VERSION ""

NS_ :

BS_:

BU_: ServiceTool DUT

BO_ 2565537529 RQST_0000: 3 ServiceTool
 SG_ ParameterGroupNumber : 0|24@1+ (1,0) [0|16777215] ""  DUT

BO_ 2566838521 CA_ST: 9 ServiceTool
 SG_ AddressAssignment : 64|8@1+ (1,0) [0|255] ""  DUT
 SG_ ArbitraryAddressCapable : 63|1@1+ (1,0) [0|1] ""  DUT
 SG_ IndustryGroup M : 60|3@1+ (1,0) [0|7] ""  DUT
 SG_ VehicleSystemInstance : 56|4@1+ (1,0) [0|15] ""  DUT
 SG_ Function : 40|8@1+ (1,0) [0|255] ""  DUT
 SG_ VehicleSystem m0 : 49|7@1+ (1,0) [0|127] ""  DUT
 SG_ FunctionInstance : 35|5@1+ (1,0) [0|31] ""  DUT
 SG_ ECUInstance : 32|3@1+ (1,0) [0|7] ""  DUT
 SG_ ManufacturerCode : 21|11@1+ (1,0) [0|2047] ""  DUT
 SG_ IdentityNumber : 0|21@1+ (1,0) [0|2097152] ""  DUT
 SG_ VehicleSystem5 m5 : 49|7@1+ (1,0) [0|127] ""  DUT
 SG_ VehicleSystem4 m4 : 49|7@1+ (1,0) [0|127] ""  DUT
 SG_ VehicleSystem3 m3 : 49|7@1+ (1,0) [0|127] ""  DUT
 SG_ VehicleSystem2 m2 : 49|7@1+ (1,0) [0|127] ""  DUT
 SG_ VehicleSystem1 m1 : 49|7@1+ (1,0) [0|127] ""  DUT

BO_ 2565799678 ACL: 8 Vector__XXX
 SG_ VehicleSystem1 m1 : 49|7@1+ (1,0) [0|127] "" Vector__XXX
 SG_ VehicleSystem2 m2 : 49|7@1+ (1,0) [0|127] "" Vector__XXX
 SG_ VehicleSystem3 m3 : 49|7@1+ (1,0) [0|127] "" Vector__XXX
 SG_ VehicleSystem4 m4 : 49|7@1+ (1,0) [0|127] "" Vector__XXX
 SG_ VehicleSystem5 m5 : 49|7@1+ (1,0) [0|127] "" Vector__XXX
 SG_ VehicleSystem m0 : 49|7@1+ (1,0) [0|127] "" Vector__XXX
 SG_ IdentityNumber : 0|21@1+ (1,0) [0|2097152] "" Vector__XXX
 SG_ ManufacturerCode : 21|11@1+ (1,0) [0|2047] "" Vector__XXX
 SG_ ECUInstance : 32|3@1+ (1,0) [0|7] "" Vector__XXX
 SG_ FunctionInstance : 35|5@1+ (1,0) [0|31] "" Vector__XXX
 SG_ Function : 40|8@1+ (1,0) [0|255] "" Vector__XXX
 SG_ VehicleSystemInstance : 56|4@1+ (1,0) [0|15] "" Vector__XXX
 SG_ IndustryGroup M : 60|3@1+ (1,0) [0|7] "" Vector__XXX
 SG_ ArbitraryAddressCapable : 63|1@1+ (1,0) [0|1] "" Vector__XXX

BO_ 2566838912 SOFT_DUT: 8 DUT
 SG_ NmbrOfSftwreIdentificationFields : 0|8@1+ (1,0) [0|250] "steps" Vector__XXX
 SG_ SoftwareIdentification : 8|8@1+ (1.02,0) [0|255] "per byte" Vector__XXX

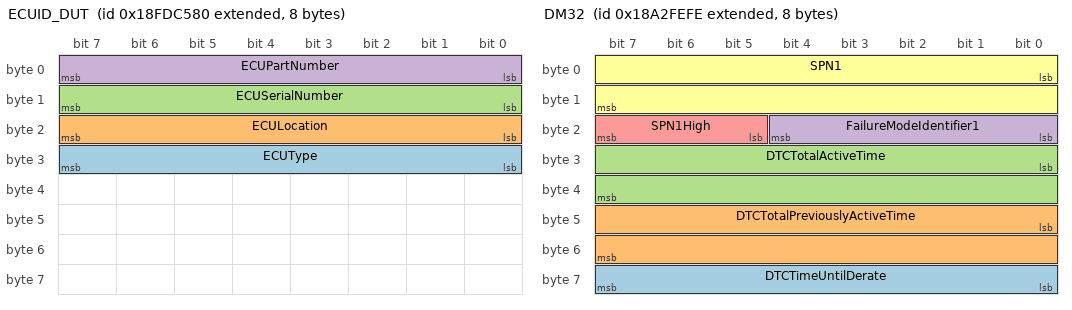
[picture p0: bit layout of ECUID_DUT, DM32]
BO_ 2566768000 ECUID_DUT: 8 DUT
 SG_ ECUType : 24|8@1+ (1.02,0) [0|255] "per byte" Vector__XXX
 SG_ ECULocation : 16|8@1+ (1.02,0) [0|255] "per byte" Vector__XXX
 SG_ ECUSerialNumber : 8|8@1+ (1.02,0) [0|255] "per byte" Vector__XXX
 SG_ ECUPartNumber : 0|8@1+ (1.02,0) [0|255] "per byte" Vector__XXX

BO_ 2565799673 ACL_ST: 8 ServiceTool
 SG_ ArbitraryAddressCapable : 63|1@1+ (1,0) [0|1] "" Vector__XXX
 SG_ IndustryGroup M : 60|3@1+ (1,0) [0|7] "" Vector__XXX
 SG_ VehicleSystemInstance : 56|4@1+ (1,0) [0|15] "" Vector__XXX
 SG_ Function : 40|8@1+ (1,0) [0|255] "" Vector__XXX
 SG_ FunctionInstance : 35|5@1+ (1,0) [0|31] "" Vector__XXX
 SG_ ECUInstance : 32|3@1+ (1,0) [0|7] "" Vector__XXX
 SG_ ManufacturerCode : 21|11@1+ (1,0) [0|2047] "" Vector__XXX
 SG_ IdentityNumber : 0|21@1+ (1,0) [0|2097152] "" Vector__XXX
 SG_ VehicleSystem m0 : 49|7@1+ (1,0) [0|127] "" Vector__XXX
 SG_ VehicleSystem5 m5 : 49|7@1+ (1,0) [0|127] "" Vector__XXX
 SG_ VehicleSystem4 m4 : 49|7@1+ (1,0) [0|127] "" Vector__XXX
 SG_ VehicleSystem3 m3 : 49|7@1+ (1,0) [0|127] "" Vector__XXX
 SG_ VehicleSystem2 m2 : 49|7@1+ (1,0) [0|127] "" Vector__XXX
 SG_ VehicleSystem1 m1 : 49|7@1+ (1,0) [0|127] "" Vector__XXX

BO_ 2565799552 ACL_DUT: 8 DUT
 SG_ ArbitraryAddressCapable : 63|1@1+ (1,0) [0|1] "" Vector__XXX
 SG_ IndustryGroup M : 60|3@1+ (1,0) [0|7] "" Vector__XXX
 SG_ VehicleSystemInstance : 56|4@1+ (1,0) [0|15] "" Vector__XXX
 SG_ Function : 40|8@1+ (1,0) [0|255] "" Vector__XXX
 SG_ FunctionInstance : 35|5@1+ (1,0) [0|31] "" Vector__XXX
 SG_ ECUInstance : 32|3@1+ (1,0) [0|7] "" Vector__XXX
 SG_ ManufacturerCode : 21|11@1+ (1,0) [0|2047] "" Vector__XXX
 SG_ IdentityNumber : 0|21@1+ (1,0) [0|2097152] "" Vector__XXX
 SG_ VehicleSystem m0 : 49|7@1+ (1,0) [0|127] "" Vector__XXX
 SG_ VehicleSystem5 m5 : 49|7@1+ (1,0) [0|127] "" Vector__XXX
 SG_ VehicleSystem4 m4 : 49|7@1+ (1,0) [0|127] "" Vector__XXX
 SG_ VehicleSystem3 m3 : 49|7@1+ (1,0) [0|127] "" Vector__XXX
 SG_ VehicleSystem2 m2 : 49|7@1+ (1,0) [0|127] "" Vector__XXX
 SG_ VehicleSystem1 m1 : 49|7@1+ (1,0) [0|127] "" Vector__XXX

BO_ 2562785152 SensorOutput_DUT: 8 DUT
 SG_ SensorDummy : 0|8@1+ (1,0) [0|0] ""  ServiceTool

BO_ 2562785278 SensorOutput: 8 Vector__XXX
 SG_ SensorDummy : 0|8@1+ (1,0) [0|0] "" Vector__XXX

BO_ 2632712064 TPDT_DUT: 8 DUT
 SG_ SequenceNumber : 0|8@1+ (1,0) [0|255] ""  ServiceTool

BO_ 2632777600 TPCM_DUT: 8 DUT
 SG_ TotalNumberOfPacketsEoMA m19 : 24|8@1+ (1,0) [0|255] ""  ServiceTool
 SG_ TotalMessageSizeEoMA m19 : 8|16@1+ (1,0) [0|64255] "counts"  ServiceTool
 SG_ TotalMessageSizeBAM m32 : 8|16@1+ (1,0) [0|64255] "counts"  ServiceTool
 SG_ TotalNumberOfPacketsBAM m32 : 24|8@1+ (1,0) [0|255] ""  ServiceTool
 SG_ ConnectionAbortReason m255 : 8|8@1+ (1,0) [0|255] ""  ServiceTool
 SG_ NextPacketNumberToBeSent m17 : 16|8@1+ (1,0) [0|255] ""  ServiceTool
 SG_ NumberOfPacketsThatCanBeSent m17 : 8|8@1+ (1,0) [0|255] ""  ServiceTool
 SG_ PGNumber : 40|24@1+ (1,0) [0|16777200] ""  ServiceTool
 SG_ MaximumNumberOfPackets m16 : 32|8@1+ (1,0) [0|255] ""  ServiceTool
 SG_ TotalNumberOfPackets m16 : 24|8@1+ (1,0) [0|255] ""  ServiceTool
 SG_ TotalMessageSize m16 : 8|16@1+ (1,0) [0|64255] "counts"  ServiceTool
 SG_ ControlByte M : 0|8@1+ (1,0) [0|255] ""  ServiceTool

BO_ 2560818942 DM32: 8 Vector__XXX
 SG_ DTCTimeUntilDerate : 56|8@1+ (0.25,0) [0|62.5] "hr" Vector__XXX
 SG_ DTCTotalPreviouslyActiveTime : 40|16@1+ (0.2,0) [0|12851] "hr" Vector__XXX
 SG_ DTCTotalActiveTime : 24|16@1+ (0.2,0) [0|12851] "hr" Vector__XXX
 SG_ FailureModeIdentifier1 : 16|5@1+ (1,0) [0|0] "" Vector__XXX
 SG_ SPN1High : 21|3@1+ (1,0) [0|7] "" Vector__XXX
 SG_ SPN1 : 0|16@1+ (1,0) [0|65536] "" Vector__XXX

BO_ 2566764798 DM26: 8 Vector__XXX
 SG_ NMHCConvertingCatalystCompleted : 60|1@1+ (1,0) [0|1] "" Vector__XXX
 SG_ NMHCConvertingCatalystEnabled : 44|1@1+ (1,0) [0|1] "" Vector__XXX
 SG_ NOxConvertingCatalystAdsorberCom : 59|1@1+ (1,0) [0|1] "" Vector__XXX
 SG_ NOxConvertingCatalystAdsorberEna : 43|1@1+ (1,0) [0|1] "" Vector__XXX
 SG_ DieselParticulateFilterCompleted : 58|1@1+ (1,0) [0|1] "" Vector__XXX
 SG_ DieselParticulateFilterEnabled : 42|1@1+ (1,0) [0|1] "" Vector__XXX
 SG_ BoostPressureControlSystemComple : 57|1@1+ (1,0) [0|1] "" Vector__XXX
 SG_ BoostPressureControlSystemEnable : 41|1@1- (1,0) [0|0] "" Vector__XXX
 SG_ MisfireMonitoringComplete : 28|1@1+ (1,0) [0|1] "" Vector__XXX
 SG_ MisfireMonitoringEnabled : 24|1@1+ (1,0) [0|0] "" Vector__XXX
 SG_ FuelSystemMonitoringEnabled : 25|1@1+ (1,0) [0|1] "" Vector__XXX
 SG_ ComprehensiveComptMonComplete : 30|1@1+ (1,0) [0|1] "" Vector__XXX
 SG_ ComprehensiveCompMonEnabled : 26|1@1+ (1,0) [0|1] "" Vector__XXX
 SG_ SecondAirSystemMonComplete : 51|1@1+ (1,0) [0|1] "" Vector__XXX
 SG_ SecondAirSystemMonEnabled : 35|1@1+ (1,0) [0|1] "" Vector__XXX
 SG_ OxygenSensorMonComplete : 53|1@1+ (1,0) [0|1] "" Vector__XXX
 SG_ OxygenSensorMonEnabled : 37|1@1+ (1,0) [0|1] "" Vector__XXX
 SG_ OxygenSensorHeaterMonComplete : 54|1@1+ (1,0) [0|1] "" Vector__XXX
 SG_ OxygenSensorHeaterMonEnabled : 38|1@1+ (1,0) [0|1] "" Vector__XXX
 SG_ HeatedCatalystMonComplete : 49|1@1+ (1,0) [0|1] "" Vector__XXX
 SG_ HeatedCatalystMonEnabled : 33|1@1+ (1,0) [0|1] "" Vector__XXX
 SG_ EvaporativeSystemMonComplete : 50|1@1+ (1,0) [0|1] "" Vector__XXX
 SG_ EvaporativeSystemMonEnabled : 34|1@1+ (1,0) [0|1] "" Vector__XXX
 SG_ EGRSystemMonitoringComplete : 55|1@1+ (1,0) [0|1] "" Vector__XXX
 SG_ EGRSystemMonitoringEnabled : 39|1@1+ (1,0) [0|1] "" Vector__XXX
 SG_ ColdStartAidSystemMonComplete : 56|1@1+ (1,0) [0|1] "" Vector__XXX
 SG_ ColdStartAidSystemMonEnabled : 40|1@1+ (1,0) [0|1] "" Vector__XXX
 SG_ CatalystMonComplete : 48|1@1+ (1,0) [0|1] "" Vector__XXX
 SG_ CatalystMonEnabled : 32|1@1+ (1,0) [0|1] "" Vector__XXX
 SG_ ACSystemRefrigerantMonComplete : 52|1@1+ (1,0) [0|1] "" Vector__XXX
 SG_ ACSystemRefrigerantMonEnabled : 36|1@1+ (1,0) [0|1] "" Vector__XXX
 SG_ FuelSystemMonitoringComplete : 29|1@1+ (1,0) [0|1] "" Vector__XXX
 SG_ NumOfWarmUpsSinceDTCsCleared : 16|8@1+ (1,0) [0|250] "" Vector__XXX
 SG_ TimeSinceEngineStart : 0|16@1+ (1,0) [0|64255] "sec" Vector__XXX

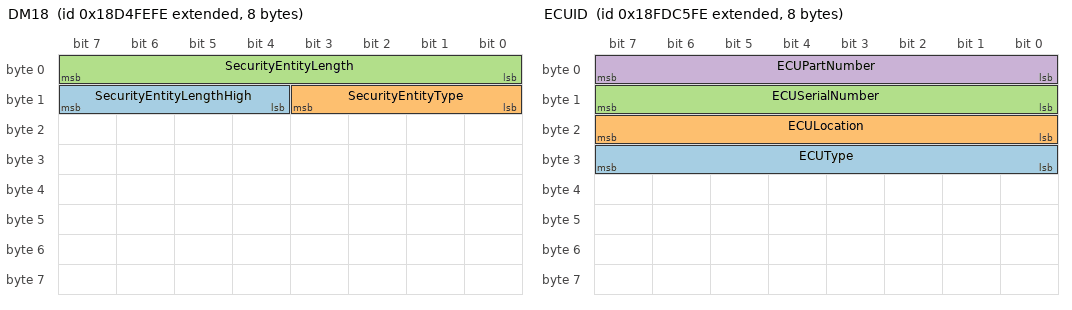
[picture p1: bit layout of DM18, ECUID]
BO_ 2564095742 DM18: 8 Vector__XXX
 SG_ SecurityEntityLengthHigh : 12|4@1+ (1,0) [0|255] "Byte" Vector__XXX
 SG_ SecurityEntityType : 8|4@1+ (1,0) [0|15] "" Vector__XXX
 SG_ SecurityEntityLength : 0|8@1+ (1,0) [0|1785] "Byte" Vector__XXX

BO_ 2566839038 SOFT: 8 Vector__XXX
 SG_ NmbrOfSftwreIdentificationFields : 0|8@1+ (1,0) [0|250] "steps" Vector__XXX
 SG_ SoftwareIdentification : 8|8@1+ (1.02,0) [0|255] "per byte" Vector__XXX

BO_ 2566768126 ECUID: 8 Vector__XXX
 SG_ ECUType : 24|8@1+ (1.02,0) [0|255] "per byte" Vector__XXX
 SG_ ECULocation : 16|8@1+ (1.02,0) [0|255] "per byte" Vector__XXX
 SG_ ECUSerialNumber : 8|8@1+ (1.02,0) [0|255] "per byte" Vector__XXX
 SG_ ECUPartNumber : 0|8@1+ (1.02,0) [0|255] "per byte" Vector__XXX

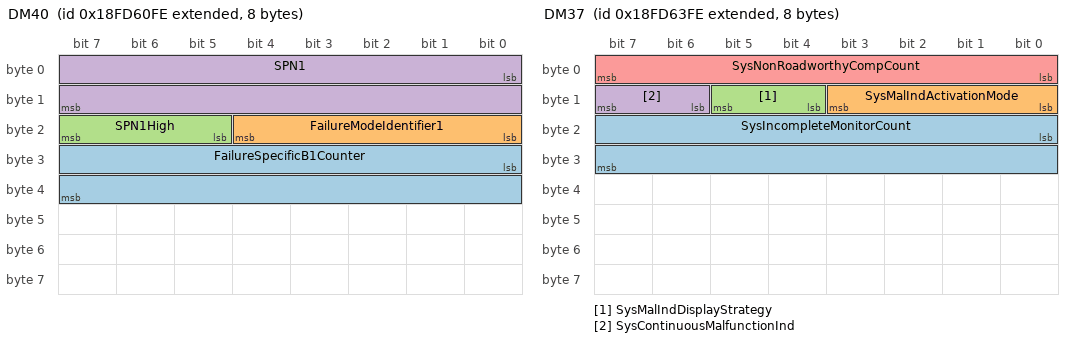
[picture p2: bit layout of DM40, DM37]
BO_ 2566742270 DM40: 8 Vector__XXX
 SG_ FailureSpecificB1Counter : 24|16@1+ (0.1,0) [0|6425.5] "hr" Vector__XXX
 SG_ FailureModeIdentifier1 : 16|5@1+ (1,0) [0|0] "" Vector__XXX
 SG_ SPN1High : 21|3@1+ (1,0) [0|7] "" Vector__XXX
 SG_ SPN1 : 0|16@1+ (1,0) [0|65536] "" Vector__XXX

BO_ 2566742526 DM39: 8 Vector__XXX
 SG_ SysGreatestB1Counter : 32|16@1+ (0.1,0) [0|6425.5] "hr" Vector__XXX
 SG_ SysCumulativeContinuousMITime : 0|32@1+ (0.05,0) [0|210554060.75] "hr" Vector__XXX

BO_ 2566742782 DM38: 8 Vector__XXX
 SG_ RegulationDescription : 0|8@1+ (1,0) [0|255] "" Vector__XXX

BO_ 2566743038 DM37: 8 Vector__XXX
 SG_ SysIncompleteMonitorCount : 16|16@1+ (1,0) [0|64512] "" Vector__XXX
 SG_ SysMalIndActivationMode : 8|4@1+ (1,0) [0|15] "" Vector__XXX
 SG_ SysMalIndDisplayStrategy : 12|2@1+ (1,0) [0|3] "" Vector__XXX
 SG_ SysContinuousMalfunctionInd : 14|2@1+ (1,0) [0|3] "" Vector__XXX
 SG_ SysNonRoadworthyCompCount : 0|8@1+ (1,0) [0|250] "" Vector__XXX

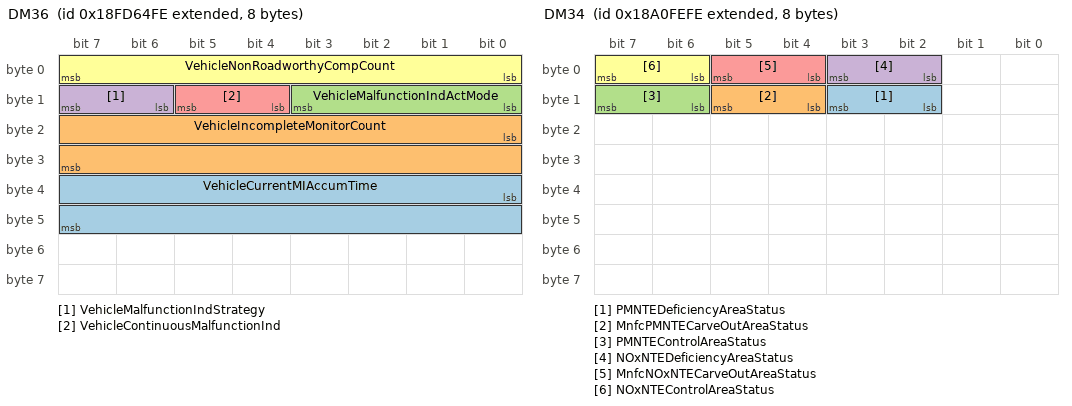
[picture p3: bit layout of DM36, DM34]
BO_ 2566743294 DM36: 8 Vector__XXX
 SG_ VehicleCurrentMIAccumTime : 32|16@1+ (1,0) [0|64255] "min" Vector__XXX
 SG_ VehicleIncompleteMonitorCount : 16|16@1+ (1,0) [0|64255] "" Vector__XXX
 SG_ VehicleMalfunctionIndActMode : 8|4@1+ (1,0) [0|15] "" Vector__XXX
 SG_ VehicleMalfunctionIndStrategy : 14|2@1+ (1,0) [0|3] "" Vector__XXX
 SG_ VehicleContinuousMalfunctionInd : 12|2@1+ (1,0) [0|3] "" Vector__XXX
 SG_ VehicleNonRoadworthyCompCount : 0|8@1+ (1,0) [0|250] "" Vector__XXX

BO_ 2560687870 DM34: 8 Vector__XXX
 SG_ PMNTEDeficiencyAreaStatus : 10|2@1+ (1,0) [0|3] "" Vector__XXX
 SG_ MnfcPMNTECarveOutAreaStatus : 12|2@1+ (1,0) [0|3] "" Vector__XXX
 SG_ PMNTEControlAreaStatus : 14|2@1+ (1,0) [0|3] "" Vector__XXX
 SG_ NOxNTEDeficiencyAreaStatus : 2|2@1+ (1,0) [0|3] "" Vector__XXX
 SG_ MnfcNOxNTECarveOutAreaStatus : 4|2@1+ (1,0) [0|3] "" Vector__XXX
 SG_ NOxNTEControlAreaStatus : 6|2@1+ (1,0) [0|3] "" Vector__XXX

BO_ 2292317950 DM33: 9 Vector__XXX
 SG_ AECDEngineHours1Timer2 : 40|32@1+ (1,0) [0|4294967295] "min" Vector__XXX
 SG_ AECDEngineHours1Timer1 : 8|32@1+ (1,0) [0|4294967295] "min" Vector__XXX
 SG_ AECDNumber1 : 0|8@1+ (1,0) [0|250] "" Vector__XXX

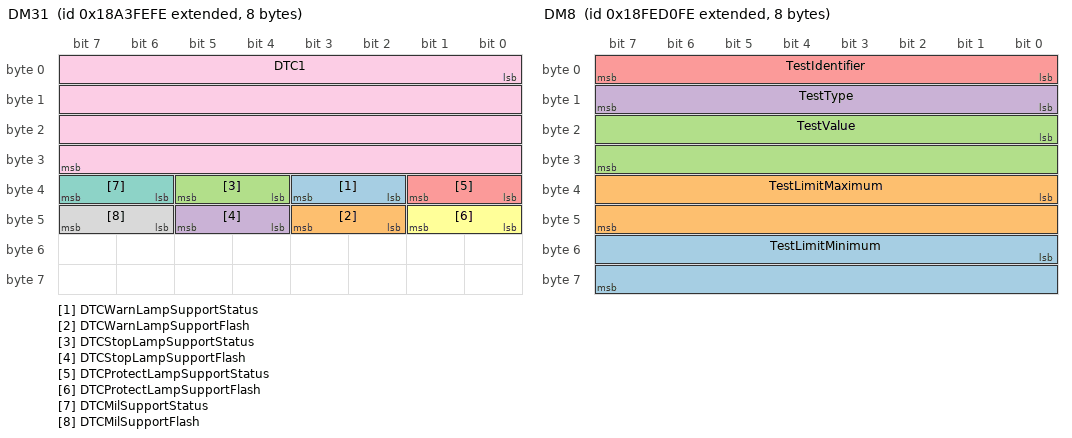
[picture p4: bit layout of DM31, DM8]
BO_ 2560884478 DM31: 8 Vector__XXX
 SG_ DTCWarnLampSupportStatus : 34|2@1+ (1,0) [0|3] "" Vector__XXX
 SG_ DTCWarnLampSupportFlash : 42|2@1+ (1,0) [0|3] "" Vector__XXX
 SG_ DTCStopLampSupportStatus : 36|2@1+ (1,0) [0|3] "" Vector__XXX
 SG_ DTCStopLampSupportFlash : 44|2@1+ (1,0) [0|3] "" Vector__XXX
 SG_ DTCProtectLampSupportStatus : 32|2@1+ (1,0) [0|3] "" Vector__XXX
 SG_ DTCProtectLampSupportFlash : 40|2@1+ (1,0) [0|3] "" Vector__XXX
 SG_ DTCMilSupportStatus : 38|2@1+ (1,0) [0|3] "" Vector__XXX
 SG_ DTCMilSupportFlash : 46|2@1+ (1,0) [0|3] "" Vector__XXX
 SG_ DTC1 : 0|32@1+ (1,0) [0|4294967295] "" Vector__XXX

BO_ 2560950014 DM30: 12 Vector__XXX
 SG_ TestLimitMinimum : 80|16@1+ (1,0) [0|64255] "" Vector__XXX
 SG_ TestLimitMaximum : 64|16@1+ (1,0) [0|64255] "" Vector__XXX
 SG_ TestValue : 48|16@1+ (1,0) [0|64255] "" Vector__XXX
 SG_ SlotId : 32|16@1+ (1,0) [0|64255] "" Vector__XXX
 SG_ TestIdentifier : 0|8@1+ (1,0) [0|255] "" Vector__XXX
 SG_ FailureModeIdentifier1 : 24|5@1+ (1,0) [0|0] "" Vector__XXX
 SG_ SPN1High : 29|3@1+ (1,0) [0|7] "" Vector__XXX
 SG_ SPN1 : 8|16@1+ (1,0) [0|65536] "" Vector__XXX

BO_ 2566836478 DM8: 8 Vector__XXX
 SG_ TestLimitMinimum : 48|16@1+ (1,0) [0|64255] "" Vector__XXX
 SG_ TestLimitMaximum : 32|16@1+ (1,0) [0|64255] "" Vector__XXX
 SG_ TestValue : 16|16@1+ (1,0) [0|64255] "" Vector__XXX
 SG_ TestType : 8|8@1+ (1,0) [1|64] "" Vector__XXX
 SG_ TestIdentifier : 0|8@1+ (1,0) [1|64] "" Vector__XXX

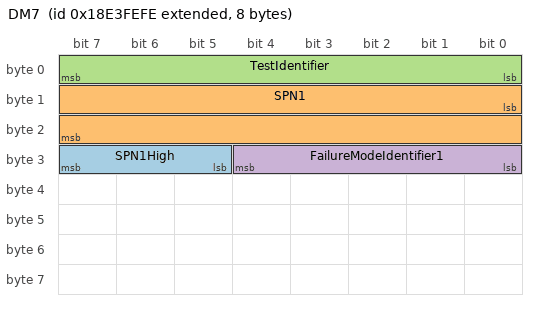
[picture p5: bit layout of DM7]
BO_ 2565078782 DM7: 8 Vector__XXX
 SG_ SPN1High : 29|3@1+ (1,0) [0|7] "" Vector__XXX
 SG_ SPN1 : 8|16@1+ (1,0) [0|65536] "" Vector__XXX
 SG_ TestIdentifier : 0|8@1+ (1,0) [1|64] "" Vector__XXX
 SG_ FailureModeIdentifier1 : 24|5@1+ (1,0) [0|0] "" Vector__XXX

BO_ 2566836222 DM6: 22 Vector__XXX
 SG_ FlashRedStopLamp : 12|2@1+ (1,0) [0|3] "" Vector__XXX
 SG_ FlashProtectLamp : 8|2@1+ (1,0) [0|3] "" Vector__XXX
 SG_ FlashMalfuncIndicatorLamp : 14|2@1+ (1,0) [0|3] "" Vector__XXX
 SG_ FlashAmberWarningLamp : 10|2@1+ (1,0) [0|3] "" Vector__XXX
 SG_ MalfunctionIndicatorLampStatus : 6|2@1+ (1,0) [0|3] "" Vector__XXX
 SG_ RedStopLampState : 4|2@1+ (1,0) [0|3] "" Vector__XXX
 SG_ AmberWarningLampStatus : 2|2@1+ (1,0) [0|3] "" Vector__XXX
 SG_ ProtectLampStatus : 0|2@1+ (1,0) [0|3] "" Vector__XXX
 SG_ DTC5 : 144|32@1+ (1,0) [0|4294967295] "" Vector__XXX
 SG_ DTC4 : 112|32@1+ (1,0) [0|4294967295] "" Vector__XXX
 SG_ DTC3 : 80|32@1+ (1,0) [0|4294967295] "" Vector__XXX
 SG_ DTC2 : 48|32@1+ (1,0) [0|4294967295] "" Vector__XXX
 SG_ DTC1 : 16|32@1+ (1,0) [0|4294967295] "" Vector__XXX

BO_ 2566835966 DM5: 8 Vector__XXX
 SG_ BoostPressureControlSystemStatus : 57|1@1- (1,0) [0|0] "" Vector__XXX
 SG_ DieselParticulateFilterStatus : 58|1@1- (1,0) [0|0] "" Vector__XXX
 SG_ NOxConvertingCatalystAdsorberSta : 59|1@1- (1,0) [0|0] "" Vector__XXX
 SG_ NMHCConvertingCatalystStatus : 60|1@1- (1,0) [0|0] "" Vector__XXX
 SG_ BoostPressureControlSystemSuppor : 41|1@1- (1,0) [0|0] "" Vector__XXX
 SG_ DieselParticulateFilterSupport : 42|1@1- (1,0) [0|0] "" Vector__XXX
 SG_ NOxConvertingCatalystAdsorberSup : 43|1@1- (1,0) [0|0] "" Vector__XXX
 SG_ NMHCConvertingCatalystSupport : 44|1@1- (1,0) [0|0] "" Vector__XXX
 SG_ MisfireMonitoringSupport : 24|1@1+ (1,0) [0|0] "" Vector__XXX
 SG_ OBDCompliance : 16|8@1+ (1,0) [0|240] "" Vector__XXX
 SG_ PreviouslyActiveTroubleCodes : 8|8@1+ (1,0) [0|240] "" Vector__XXX
 SG_ ActiveTroubleCodes : 0|8@1+ (1,0) [0|240] "" Vector__XXX
 SG_ SecondAirSystemMonStatus : 51|1@1+ (1,0) [0|1] "" Vector__XXX
 SG_ EvaporativeSystemMonStatus : 50|1@1+ (1,0) [0|1] "" Vector__XXX
 SG_ ACSystemRefrigerantMonStatus : 52|1@1+ (1,0) [0|1] "" Vector__XXX
 SG_ OxygenSensorHeaterMonStatus : 54|1@1+ (1,0) [0|1] "" Vector__XXX
 SG_ OxygenSensorMonStatus : 53|1@1+ (1,0) [0|1] "" Vector__XXX
 SG_ EGRSystemMonitoringStatus : 55|1@1+ (1,0) [0|1] "" Vector__XXX
 SG_ CatalystMonStatus : 48|1@1+ (1,0) [0|1] "" Vector__XXX
 SG_ ColdStartAidSystemMonStatus : 56|1@1+ (1,0) [0|1] "" Vector__XXX
 SG_ HeatedCatalystMonStatus : 49|1@1+ (1,0) [0|0] "" Vector__XXX
 SG_ CatalystMonSupp : 32|1@1+ (1,0) [0|1] "" Vector__XXX
 SG_ ColdStartAidSystemMonSupp : 40|1@1+ (1,0) [0|1] "" Vector__XXX
 SG_ HeatedCatalystMonSupp : 33|1@1+ (1,0) [0|0] "" Vector__XXX
 SG_ EvaporativeSystemMonSupp : 34|1@1+ (1,0) [0|1] "" Vector__XXX
 SG_ SecondAirSystemMonSupp : 35|1@1+ (1,0) [0|1] "" Vector__XXX
 SG_ ACSystemRefrigerantMonSupp : 36|1@1+ (1,0) [0|1] "" Vector__XXX
 SG_ OxygenSensorMonSupp : 37|1@1+ (1,0) [0|1] "" Vector__XXX
 SG_ OxygenSensorHeaterMonSupp : 38|1@1+ (1,0) [0|1] "" Vector__XXX
 SG_ EGRSystemMonitoringSupp : 39|1@1+ (1,0) [0|1] "" Vector__XXX
 SG_ MisfireMonitoringStatus : 28|1@1+ (1,0) [0|0] "" Vector__XXX
 SG_ ComprehensiveCompMonStatus : 30|1@1+ (1,0) [0|1] "" Vector__XXX
 SG_ FuelSystemMonitoringStatus : 29|1@1+ (1,0) [0|1] "" Vector__XXX
 SG_ ComprehensiveComponentMonSupp : 26|1@1+ (1,0) [0|0] "" Vector__XXX
 SG_ FuelSystemMonitoringSupport : 25|1@1+ (1,0) [0|1] "" Vector__XXX

BO_ 2566835710 DM4: 13 Vector__XXX
 SG_ EngIntakeManifold1Press : 48|8@1+ (2,0) [0|500] "kPa" Vector__XXX
 SG_ FreezeFrameLength : 0|8@1+ (1,0) [0|255] "Byte" Vector__XXX
 SG_ EngSpeed : 56|16@1+ (0.125,0) [0|8031.875] "rpm" Vector__XXX
 SG_ EngTorqueMode : 40|4@1+ (1,0) [0|15] "" Vector__XXX
 SG_ WheelBasedVehicleSpeed : 88|16@1+ (0.0039062485409696,0) [0|250.996] "km/h" Vector__XXX
 SG_ EngPercentLoadAtCurrentSpeed : 72|8@1+ (1,0) [0|250] "%" Vector__XXX
 SG_ EngCoolantTemp : 80|8@1+ (1,-40) [-40|210] "deg C" Vector__XXX
 SG_ DTC1 : 8|32@1+ (1,0) [0|4294967295] "" Vector__XXX

BO_ 2566835454 DM3: 0 Vector__XXX

BO_ 2566764542 DM25: 13 Vector__XXX
 SG_ ExpandedFreezeFrameLength : 0|8@1+ (1,0) [0|255] "Byte" Vector__XXX
 SG_ DTC1 : 8|32@1+ (1,0) [0|4294967295] "" Vector__XXX

BO_ 2566764286 DM24: 12 Vector__XXX
 SG_ SPNSupported1High : 21|3@1+ (1,0) [0|7] "" Vector__XXX
 SG_ SPNSupportTypeSTR3 : 82|1@1+ (1,0) [0|1] "" Vector__XXX
 SG_ SPNSupportTypeSTR2 : 50|1@1+ (1,0) [0|1] "" Vector__XXX
 SG_ SPNSupportTypeEFF3 : 80|1@1+ (1,0) [0|1] "" Vector__XXX
 SG_ SPNSupportTypeEFF2 : 48|1@1+ (1,0) [0|1] "" Vector__XXX
 SG_ SPNSupportTypeDS3 : 81|1@1+ (1,0) [0|1] "" Vector__XXX
 SG_ SPNSupportTypeDS2 : 49|1@1+ (1,0) [0|1] "" Vector__XXX
 SG_ SPNSupported3High : 85|3@1+ (1,0) [0|7] "" Vector__XXX
 SG_ SPNSupported2High : 53|3@1+ (1,0) [0|7] "" Vector__XXX
 SG_ SPNSupported3 : 64|16@1+ (1,0) [0|65535] "" Vector__XXX
 SG_ SPNSupported2 : 32|16@1+ (1,0) [0|65535] "" Vector__XXX
 SG_ SPNDataLength3 : 88|8@1+ (1,0) [0|240] "" Vector__XXX
 SG_ SPNSupportTypeSTR1 : 18|1@1+ (1,0) [0|1] "" Vector__XXX
 SG_ SPNSupportTypeDS1 : 17|1@1+ (1,0) [0|1] "" Vector__XXX
 SG_ SPNSupportTypeEFF1 : 16|1@1+ (1,0) [0|1] "" Vector__XXX
 SG_ SPNDataLength2 : 56|8@1+ (1,0) [0|240] "" Vector__XXX
 SG_ SPNDataLength1 : 24|8@1+ (1,0) [0|240] "" Vector__XXX
 SG_ SPNSupported1 : 0|16@1+ (1,0) [0|65535] "" Vector__XXX

CM_ BO_ 2565537529 "Request";
CM_ SG_ 2565537529 ParameterGroupNumber "PGN which is requested by Request2 message";
CM_ BO_ 2566838521 "Commanded Address";
CM_ SG_ 2566838521 AddressAssignment "The source address that is to be assigned to the CA that has the NAME corresponding to the one conveyed in the first eight bytes of this Commanded Address message.";
CM_ SG_ 2566838521 IndustryGroup "0 = Global; 
   1  = On-Highway; 
   2  = Agricultural and Forestry; 
   3  = Construction; 
   4  = Marine;
   5  = Industrial - Process
          Control - Stationary (Gen-Sets)
   6  = Reserve for SAE
   7  = Reserve for SAE";
CM_ SG_ 2566838521 ManufacturerCode "Assigned by NMEA 2000 Committee";
CM_ BO_ 2565799678 "Address Claimed";
CM_ SG_ 2565799678 ManufacturerCode "Assigned by NMEA 2000 Committee";
CM_ SG_ 2565799678 IndustryGroup "0 = Global; 
   1  = On-Highway; 
   2  = Agricultural and Forestry; 
   3  = Construction; 
   4  = Marine;
   5  = Industrial - Process
          Control - Stationary (Gen-Sets)
   6  = Reserve for SAE
   7  = Reserve for SAE";
CM_ BO_ 2566838912 "Byte: 1 Number of software identification fields";
CM_ SG_ 2566838912 NmbrOfSftwreIdentificationFields "Number of software identification designators represented in the software identification parameter group.";
CM_ SG_ 2566838912 SoftwareIdentification "Software identification of an electronic module. As an example, this parameter may be represented with ASCII characters";
CM_ BO_ 2566768000 "Message for reporting identification and information about the physical ECU and its hardware, such as the ECU's part";
CM_ SG_ 2566768000 ECUType "The type of ECU. One example of a use of the ECU type could be for classifying ECU capabilities, such as I/O.";
CM_ SG_ 2566768000 ECULocation "The location of the ECU within a network.";
CM_ SG_ 2566768000 ECUSerialNumber "The serial number of the physical ECU.";
CM_ SG_ 2566768000 ECUPartNumber "The part number of the physical ECU.";
CM_ BO_ 2565799673 "Address Claimed";
CM_ SG_ 2565799673 IndustryGroup "0 = Global; 
   1  = On-Highway; 
   2  = Agricultural and Forestry; 
   3  = Construction; 
   4  = Marine;
   5  = Industrial - Process
          Control - Stationary (Gen-Sets)
   6  = Reserve for SAE
   7  = Reserve for SAE";
CM_ SG_ 2565799673 ManufacturerCode "Assigned by NMEA 2000 Committee";
CM_ BO_ 2565799552 "Address Claimed";
CM_ SG_ 2565799552 IndustryGroup "0 = Global; 
   1  = On-Highway; 
   2  = Agricultural and Forestry; 
   3  = Construction; 
   4  = Marine;
   5  = Industrial - Process
          Control - Stationary (Gen-Sets)
   6  = Reserve for SAE
   7  = Reserve for SAE";
CM_ SG_ 2565799552 ManufacturerCode "Assigned by NMEA 2000 Committee";
CM_ BO_ 2632712064 "Transport Protocol - Data Transfer";
CM_ BO_ 2632777600 "Transport Protocol - Connection Management";
CM_ SG_ 2632777600 TotalNumberOfPacketsEoMA "Total number of packets for BAM message.Total number of packets received for RTS/CTS message.Total number of packets for RTS/CTS message.";
CM_ SG_ 2632777600 TotalMessageSizeEoMA "Total message size (in bytes) for BAM message.Total message size (in bytes) for RTS/CTS message.Total message size (in bytes) for RTS/CTS message.";
CM_ SG_ 2632777600 TotalMessageSizeBAM "Total message size (in bytes) for BAM message.Total message size (in bytes) for RTS/CTS message.Total message size (in bytes) for RTS/CTS message.";
CM_ SG_ 2632777600 TotalNumberOfPacketsBAM "Total number of packets for BAM message.Total number of packets received for RTS/CTS message.Total number of packets for RTS/CTS message.";
CM_ SG_ 2632777600 ConnectionAbortReason "Reason for connection abort message.";
CM_ SG_ 2632777600 NextPacketNumberToBeSent "Next Packet Number to be sent (TP.CM_CTS)";
CM_ SG_ 2632777600 NumberOfPacketsThatCanBeSent "Number of Packets that can be sent (TP.CM_CTS)";
CM_ SG_ 2632777600 MaximumNumberOfPackets "Maximum number of packets for RTS/CTS message.";
CM_ SG_ 2632777600 TotalNumberOfPackets "Total number of packets for BAM message.Total number of packets received for RTS/CTS message.Total number of packets for RTS/CTS message.";
CM_ SG_ 2632777600 TotalMessageSize "Total message size (in bytes) for BAM message.Total message size (in bytes) for RTS/CTS message.Total message size (in bytes) for RTS/CTS message.";
CM_ BO_ 2560818942 "DM32 provides the DTCs and associated timers";
CM_ SG_ 2560818942 DTCTimeUntilDerate "This timer provides the number of hours the malfunction has until the OBD required derate will occur";
CM_ SG_ 2560818942 DTCTotalPreviouslyActiveTime "This timer provides the number of hours the NOx malfunction has been confirmed and previously active";
CM_ SG_ 2560818942 DTCTotalActiveTime "This timer provides the total number of hours the DTC has been confirmed and active";
CM_ SG_ 2560818942 FailureModeIdentifier1 "The FMI defines the type of failure detected in the subsystem identified by an SPN.";
CM_ SG_ 2560818942 SPN1High "SPN #1 (Conversion Version 4)";
CM_ SG_ 2560818942 SPN1 "SPN #1 (Conversion Version 4)";
CM_ BO_ 2566764798 "Diagnostic readiness 3";
CM_ BO_ 2564095742 "Data security";
CM_ BO_ 2566839038 "Byte: 1 Number of software identification fields";
CM_ SG_ 2566839038 NmbrOfSftwreIdentificationFields "Number of software identification designators represented in the software identification parameter group.";
CM_ SG_ 2566839038 SoftwareIdentification "Software identification of an electronic module. As an example, this parameter may be represented with ASCII characters";
CM_ BO_ 2566768126 "Message for reporting identification and information about the physical ECU and its hardware, such as the ECU's part";
CM_ SG_ 2566768126 ECUType "The type of ECU. One example of a use of the ECU type could be for classifying ECU capabilities, such as I/O.";
CM_ SG_ 2566768126 ECULocation "The location of the ECU within a network.";
CM_ SG_ 2566768126 ECUSerialNumber "The serial number of the physical ECU.";
CM_ SG_ 2566768126 ECUPartNumber "The part number of the physical ECU.";
CM_ BO_ 2566742270 "HB1C provides the system specific individual B1 failure counters";
CM_ SG_ 2566742270 FailureSpecificB1Counter "The Failure Specific B1 Counter provides an individual B1 counter";
CM_ SG_ 2566742270 FailureModeIdentifier1 "The FMI defines the type of failure detected in the subsystem identified by an SPN.";
CM_ SG_ 2566742270 SPN1High "SPN #1 (Conversion Version 4)";
CM_ SG_ 2566742270 SPN1 "SPN #1 (Conversion Version 4)";
CM_ BO_ 2566742526 "Cumulative Continuous MI-System";
CM_ SG_ 2566742526 SysGreatestB1Counter "System Greatest B1 Counter";
CM_ SG_ 2566742526 SysCumulativeContinuousMITime "System Cumulative Continuous MI Time";
CM_ BO_ 2566742782 "Harmonized Global Regulation Description";
CM_ SG_ 2566742782 RegulationDescription "Global Technical Regulation Description";
CM_ BO_ 2566743038 "Harmonized Roadworthiness";
CM_ SG_ 2566743038 SysIncompleteMonitorCount "System Incomplete Monitor Count";
CM_ SG_ 2566743038 SysMalIndActivationMode "System Malfunction Indicator Status";
CM_ SG_ 2566743038 SysMalIndDisplayStrategy "System Malfunction Indicator Display";
CM_ SG_ 2566743038 SysContinuousMalfunctionInd "System Continuous Malfunction Indicator";
CM_ SG_ 2566743038 SysNonRoadworthyCompCount "System Non-Roadworthy Component Count";
CM_ BO_ 2566743294 "Harmonized Roadworthiness ";
CM_ SG_ 2566743294 VehicleCurrentMIAccumTime "Vehicle Current MI Accumulated Time";
CM_ SG_ 2566743294 VehicleIncompleteMonitorCount "Vehicle Incomplete Monitor Count";
CM_ SG_ 2566743294 VehicleMalfunctionIndActMode "Vehicle Malfunction Indicator Status ";
CM_ SG_ 2566743294 VehicleMalfunctionIndStrategy "Vehicle Malfunction Indicator Display Strategy ";
CM_ SG_ 2566743294 VehicleContinuousMalfunctionInd "Vehicle Continuous Malfunction Indicator";
CM_ SG_ 2566743294 VehicleNonRoadworthyCompCount "Vehicle Non-Roadworthy Component Count";
CM_ BO_ 2560687870 "The status of engine operating in the NTE control areas for given pollutants, such as NOx and PM";
CM_ SG_ 2560687870 PMNTEDeficiencyAreaStatus "Status of engine operation within the PM NTE Deficiency Area";
CM_ SG_ 2560687870 MnfcPMNTECarveOutAreaStatus "Status of engine operation within the manufacturer specific PM NTE carve out area";
CM_ SG_ 2560687870 PMNTEControlAreaStatus "Status of engine operation within the bounded region of the engine's torque and speed map.";
CM_ SG_ 2560687870 NOxNTEDeficiencyAreaStatus "Status of engine operation within the NOx NTE Deficiency Area";
CM_ SG_ 2560687870 MnfcNOxNTECarveOutAreaStatus "Status of engine operation within the bounded region of the engine's torque and speed map.";
CM_ SG_ 2560687870 NOxNTEControlAreaStatus "Status of engine operation within the bounded region of the engine's torque and speed map.";
CM_ BO_ 2292317950 "The total engine run time while each of the Emission Increasing Auxiliary Emission Control Devices is active";
CM_ SG_ 2292317950 AECDEngineHours1Timer2 "The total engine running hours recorded in the second timer for the EI-AECD";
CM_ SG_ 2292317950 AECDEngineHours1Timer1 "The total engine running hours recorded in the first timer for the EI-AECD";
CM_ SG_ 2292317950 AECDNumber1 "The manufacturer assigned number for the specific EI-AECD";
CM_ BO_ 2560884478 "This message shall provide the applicable lamp for each individual DTC";
CM_ SG_ 2560884478 DTCWarnLampSupportStatus "Lamp support status";
CM_ SG_ 2560884478 DTCWarnLampSupportFlash "Lamp support status";
CM_ SG_ 2560884478 DTCStopLampSupportStatus "Lamp support status";
CM_ SG_ 2560884478 DTCStopLampSupportFlash "Lamp support status";
CM_ SG_ 2560884478 DTCProtectLampSupportStatus "Lamp support status";
CM_ SG_ 2560884478 DTCProtectLampSupportFlash "Lamp support status";
CM_ SG_ 2560884478 DTCMilSupportStatus "Lamp support status";
CM_ SG_ 2560884478 DTCMilSupportFlash "Lamp support status";
CM_ SG_ 2560884478 DTC1 "Diagnostic Trouble Code";
CM_ BO_ 2560950014 "This message conveys the scaled test results for the applicable test requested in DM7.";
CM_ SG_ 2560950014 TestLimitMinimum "The test value must be greater than or equal to Test Limit Minimum in order for the test to pass";
CM_ SG_ 2560950014 TestLimitMaximum "The test value must be less than or equal to Test Limit Maximum in order for the test to pass.";
CM_ SG_ 2560950014 TestValue "The test value collected during the test.";
CM_ SG_ 2560950014 SlotId "The SLOT Identifer is used to determine the multiplier and offset to be used to scale the test value.";
CM_ SG_ 2560950014 TestIdentifier "Test Identifier";
CM_ SG_ 2560950014 FailureModeIdentifier1 "The FMI defines the type of failure detected in the subsystem identified by an SPN.";
CM_ SG_ 2560950014 SPN1High "SPN #1 (Conversion Version 4)";
CM_ SG_ 2560950014 SPN1 "SPN #1 (Conversion Version 4)";
CM_ BO_ 2566836478 "Test results for non-continously monitored systems.";
CM_ SG_ 2566836478 TestLimitMinimum "The threshold which the test value must be above to pass the test.";
CM_ SG_ 2566836478 TestLimitMaximum "The threshold which the test value must be below to pass the test.";
CM_ SG_ 2566836478 TestValue "The test value collected during the test.";
CM_ SG_ 2566836478 TestType "Identifies the non-continously monitored component identifier that was tested.";
CM_ SG_ 2566836478 TestIdentifier "Designates the test to be run.";
CM_ BO_ 2565078782 "Command non-continously monitored test";
CM_ SG_ 2565078782 SPN1High "SPN #1 (Conversion Version 4)";
CM_ SG_ 2565078782 SPN1 "SPN #1 (Conversion Version 4)";
CM_ SG_ 2565078782 TestIdentifier "Designates the test to be run.";
CM_ SG_ 2565078782 FailureModeIdentifier1 "The FMI defines the type of failure detected in the subsystem identified by an SPN.";
CM_ BO_ 2566836222 "Pending DTCs";
CM_ SG_ 2566836222 FlashRedStopLamp "This parameter provides the capability to flash the RSL (SPN 3039).";
CM_ SG_ 2566836222 FlashProtectLamp "This parameter provides the capability to flash the engine protect lamp (SPN 3041).";
CM_ SG_ 2566836222 FlashMalfuncIndicatorLamp "This parameter provides the capability to flash the MIL (SPN 3038).";
CM_ SG_ 2566836222 FlashAmberWarningLamp "This parameter provides the capability to flash the AWL (SPN 3040). ";
CM_ SG_ 2566836222 MalfunctionIndicatorLampStatus "A lamp used to relay only emissions-related trouble code information.";
CM_ SG_ 2566836222 RedStopLampState "This lamp is uesed to relay trouble code information that is of a severe enought condition that it warrants stopping the vehicle.";
CM_ SG_ 2566836222 AmberWarningLampStatus "This lamp is used to relay trouble code information that is reporting a problem with the vehicle system but the vehicle need
not be immediately stopped.";
CM_ SG_ 2566836222 ProtectLampStatus "This lamp is used to relay trouble code informatio that is reporting a problem with a vehicle system that is most
probably not electronic subsystem related.";
CM_ SG_ 2566836222 DTC5 "Diagnostic Trouble Code";
CM_ SG_ 2566836222 DTC4 "Diagnostic Trouble Code";
CM_ SG_ 2566836222 DTC3 "Diagnostic Trouble Code";
CM_ SG_ 2566836222 DTC2 "Diagnostic Trouble Code";
CM_ SG_ 2566836222 DTC1 "Diagnostic Trouble Code";
CM_ BO_ 2566835966 "Diagnostic readiness 1";
CM_ SG_ 2566835966 OBDCompliance "Identifies the OBD compliance capabilityof the responding controller.";
CM_ SG_ 2566835966 PreviouslyActiveTroubleCodes "Identifies the number of previously active trouble codes that are present in a specific controller.";
CM_ SG_ 2566835966 ActiveTroubleCodes "Identifies the number of active trouble codes that are present in a specific controller.";
CM_ BO_ 2566835710 "Freeze frame parameters";
CM_ SG_ 2566835710 EngIntakeManifold1Press "The gage pressure measurement of the air intake manifold. If there are multiple air pressure sensors in the intake stream,";
CM_ SG_ 2566835710 FreezeFrameLength "The freeze frame length shall be equal to the number of bytes in the required parameters plus the number of bytes in the
manufacturer specific parameters.";
CM_ SG_ 2566835710 EngSpeed "Actual engine speed which is calculated over a minimum crankshaft angle of 720 degrees divided by the number of";
CM_ SG_ 2566835710 EngTorqueMode "State signal which indicates which engine torque mode is currently generating, limiting, or controlling the torque. Note";
CM_ SG_ 2566835710 WheelBasedVehicleSpeed "Speed of the vehicle as calculated from wheel or tailshaft speed.";
CM_ SG_ 2566835710 EngPercentLoadAtCurrentSpeed "The ratio of actual engine percent torque (indicated) to maximum indicated torque available at the current engine speed,";
CM_ SG_ 2566835710 EngCoolantTemp "Temperature of liquid found in engine cooling system.";
CM_ SG_ 2566835710 DTC1 "Diagnostic Trouble Code";
CM_ BO_ 2566835454 "Diagnostic data clear/reset of previously active DTCs.";
CM_ BO_ 2566764542 "Expanded freeze frame.";
CM_ SG_ 2566764542 ExpandedFreezeFrameLength "The freeze frame length shall be equal to the number of bytes in the required parameters plus the number of bytes in the
manufacturer specific parameters.";
CM_ SG_ 2566764542 DTC1 "Diagnostic Trouble Code";
CM_ BO_ 2566764286 "SPN Support. This message is used to identify those SPNs supported by the product for freeze frames and data stream messages.";
CM_ SG_ 2566764286 SPNSupported1High "This parameter defines the SPN(s) that is/are supported for the freeze frame and/or data stream information.";
CM_ SG_ 2566764286 SPNSupportTypeSTR3 "This parameter defines whether the applicable parameter (that is the SPN) is supported in the freeze frame, the data stream or both the freeze frame and data stream.";
CM_ SG_ 2566764286 SPNSupportTypeSTR2 "This parameter defines whether the applicable parameter (that is the SPN) is supported in the freeze frame, the data stream or both the freeze frame and data stream.";
CM_ SG_ 2566764286 SPNSupportTypeEFF3 "This parameter defines whether the applicable parameter (that is the SPN) is supported in the freeze frame, the data stream or both the freeze frame and data stream.";
CM_ SG_ 2566764286 SPNSupportTypeEFF2 "This parameter defines whether the applicable parameter (that is the SPN) is supported in the freeze frame, the data stream or both the freeze frame and data stream.";
CM_ SG_ 2566764286 SPNSupportTypeDS3 "This parameter defines whether the applicable parameter (that is the SPN) is supported in the freeze frame, the data stream or both the freeze frame and data stream.";
CM_ SG_ 2566764286 SPNSupportTypeDS2 "This parameter defines whether the applicable parameter (that is the SPN) is supported in the freeze frame, the data stream or both the freeze frame and data stream.";
CM_ SG_ 2566764286 SPNSupported3High "This parameter defines the SPN(s) that is/are supported for the freeze frame and/or data stream information.";
CM_ SG_ 2566764286 SPNSupported2High "This parameter defines the SPN(s) that is/are supported for the freeze frame and/or data stream information.";
CM_ SG_ 2566764286 SPNSupported3 "This parameter defines the SPN(s) that is/are supported for the freeze frame and/or data stream information.";
CM_ SG_ 2566764286 SPNSupported2 "This parameter defines the SPN(s) that is/are supported for the freeze frame and/or data stream information.";
CM_ SG_ 2566764286 SPNDataLength3 "The number of data bytes associated with the SPN in the Freeze Frame.";
CM_ SG_ 2566764286 SPNSupportTypeSTR1 "This parameter defines whether the applicable parameter (that is the SPN) is supported in the freeze frame, the data stream or both the freeze frame and data stream.";
CM_ SG_ 2566764286 SPNSupportTypeDS1 "This parameter defines whether the applicable parameter (that is the SPN) is supported in the freeze frame, the data stream or both the freeze frame and data stream.";
CM_ SG_ 2566764286 SPNSupportTypeEFF1 "This parameter defines whether the applicable parameter (that is the SPN) is supported in the freeze frame, the data stream or both the freeze frame and data stream.";
CM_ SG_ 2566764286 SPNDataLength2 "The number of data bytes associated with the SPN in the Freeze Frame.";
CM_ SG_ 2566764286 SPNDataLength1 "The number of data bytes associated with the SPN in the Freeze Frame.";
CM_ SG_ 2566764286 SPNSupported1 "This parameter defines the SPN(s) that is/are supported for the freeze frame and/or data stream information.";
BA_DEF_ SG_  "SigType" ENUM  "Default","Range","RangeSigned","ASCII","Discrete","Control","ReferencePGN","DTC","StringDelimiter","StringLength","StringLengthControl";
BA_DEF_ SG_  "GenSigStartValue" INT 0 10000;
BA_DEF_ SG_  "GenSigSendType" ENUM  "Cyclic","OnWrite","reserved","OnChange","reserved","reserved","reserved","NoSigSendType";
BA_DEF_ SG_  "GenSigILSupport" ENUM  "Yes","No";
BA_DEF_ SG_  "GenSigEVName" STRING ;
BA_DEF_ SG_  "SPN" INT 0 524287;
BA_DEF_ SG_  "SAEDocument" STRING ;
BA_DEF_ BO_  "GenMsgILSupport" ENUM  "Yes","No";
BA_DEF_ BO_  "GenMsgRequestable" INT 0 1;
BA_DEF_ BO_  "GenMsgSendType" ENUM  "cyclic","reserved","cyclicIfActive","reserved","reserved","reserved","reserved","reserved","noMsgSendType";
BA_DEF_ BO_  "VFrameFormat" ENUM  "StandardCAN","ExtendedCAN","reserved","J1939PG";
BA_DEF_ BO_  "SingleFrame" INT 0 1;
BA_DEF_ BO_  "SAE_Document" STRING ;
BA_DEF_ BU_  "NmStationAddress" INT 0 255;
BA_DEF_ BU_  "NmJ1939AAC" INT 0 1;
BA_DEF_ BU_  "NmJ1939IndustryGroup" INT 0 7;
BA_DEF_ BU_  "NmJ1939Function" INT 0 255;
BA_DEF_ BU_  "NmJ1939ManufacturerCode" INT 0 2047;
BA_DEF_ BU_  "NmJ1939IdentityNumber" INT 0 2097151;
BA_DEF_  "DatabaseVersion" STRING ;
BA_DEF_  "BusType" STRING ;
BA_DEF_  "ProtocolType" STRING ;
BA_DEF_  "SAE_J1939_75_SpecVersion" STRING ;
BA_DEF_  "SAE_J1939_21_SpecVersion" STRING ;
BA_DEF_  "SAE_J1939_73_SpecVersion" STRING ;
BA_DEF_  "SAE_J1939_71_SpecVersion" STRING ;
BA_DEF_ SG_  "SystemSignalLongSymbol" STRING ;
BA_DEF_DEF_  "SigType" "Default";
BA_DEF_DEF_  "GenSigStartValue" 0;
BA_DEF_DEF_  "GenSigSendType" "NoSigSendType";
BA_DEF_DEF_  "GenSigILSupport" "Yes";
BA_DEF_DEF_  "GenSigEVName" "Env@Nodename_@Signame";
BA_DEF_DEF_  "SPN" 0;
BA_DEF_DEF_  "SAEDocument" "";
BA_DEF_DEF_  "GenMsgILSupport" "Yes";
BA_DEF_DEF_  "GenMsgRequestable" 1;
BA_DEF_DEF_  "GenMsgSendType" "noMsgSendType";
BA_DEF_DEF_  "VFrameFormat" "J1939PG";
BA_DEF_DEF_  "SingleFrame" 1;
BA_DEF_DEF_  "SAE_Document" "";
BA_DEF_DEF_  "NmStationAddress" 254;
BA_DEF_DEF_  "NmJ1939AAC" 0;
BA_DEF_DEF_  "NmJ1939IndustryGroup" 0;
BA_DEF_DEF_  "NmJ1939Function" 0;
BA_DEF_DEF_  "NmJ1939ManufacturerCode" 0;
BA_DEF_DEF_  "NmJ1939IdentityNumber" 0;
BA_DEF_DEF_  "DatabaseVersion" "";
BA_DEF_DEF_  "BusType" "";
BA_DEF_DEF_  "ProtocolType" "";
BA_DEF_DEF_  "SAE_J1939_75_SpecVersion" "";
BA_DEF_DEF_  "SAE_J1939_21_SpecVersion" "";
BA_DEF_DEF_  "SAE_J1939_73_SpecVersion" "";
BA_DEF_DEF_  "SAE_J1939_71_SpecVersion" "";
BA_DEF_DEF_  "SystemSignalLongSymbol" "";
BA_ "DatabaseVersion" "7.5";
BA_ "BusType" "CAN";
BA_ "ProtocolType" "J1939";
BA_ "SAE_J1939_75_SpecVersion" "2005-10";
BA_ "SAE_J1939_21_SpecVersion" "2006-10";
BA_ "SAE_J1939_73_SpecVersion" "2010-10";
BA_ "SAE_J1939_71_SpecVersion" "2010-10";
BA_ "NmJ1939IdentityNumber" BU_ ServiceTool 1234;
BA_ "NmJ1939ManufacturerCode" BU_ ServiceTool 353;
BA_ "NmJ1939Function" BU_ ServiceTool 136;
BA_ "NmJ1939AAC" BU_ ServiceTool 1;
BA_ "NmStationAddress" BU_ ServiceTool 249;
BA_ "NmJ1939ManufacturerCode" BU_ DUT 343;
BA_ "NmJ1939Function" BU_ DUT 136;
BA_ "NmJ1939IndustryGroup" BU_ DUT 3;
BA_ "NmStationAddress" BU_ DUT 128;
BA_ "SAE_Document" BO_ 2565799678 "J1939-81";
BA_ "SAE_Document" BO_ 2560818942 "J1939_73";
BA_ "SAE_Document" BO_ 2566764798 "J1939-73";
BA_ "SAE_Document" BO_ 2564095742 "J1939-73";
BA_ "SAE_Document" BO_ 2566839038 "J1939-71";
BA_ "SAE_Document" BO_ 2566768126 "J1939-71";
BA_ "SAE_Document" BO_ 2566742270 "J1939_73";
BA_ "SAE_Document" BO_ 2566742526 "J1939_73";
BA_ "SAE_Document" BO_ 2566742782 "J1939_73";
BA_ "SAE_Document" BO_ 2566743038 "J1939_73";
BA_ "SAE_Document" BO_ 2566743294 "J1939_73";
BA_ "SAE_Document" BO_ 2560687870 "J1939_73";
BA_ "SAE_Document" BO_ 2292317950 "J1939_73";
BA_ "SAE_Document" BO_ 2560884478 "J1939_73";
BA_ "SAE_Document" BO_ 2560950014 "J1939_73";
BA_ "SAE_Document" BO_ 2566836478 "J1939-73";
BA_ "SAE_Document" BO_ 2565078782 "J1939-73";
BA_ "SAE_Document" BO_ 2566836222 "J1939-73";
BA_ "SAE_Document" BO_ 2566835966 "J1939-73";
BA_ "SAE_Document" BO_ 2566835710 "J1939-73";
BA_ "SAE_Document" BO_ 2566835454 "J1939-73";
BA_ "SAE_Document" BO_ 2566764542 "J1939-73";
BA_ "SAE_Document" BO_ 2566764286 "J1939-73";
BA_ "SigType" SG_ 2565537529 ParameterGroupNumber 6;
BA_ "SPN" SG_ 2565537529 ParameterGroupNumber 2574;
BA_ "SAEDocument" SG_ 2565537529 ParameterGroupNumber "J1939-21";
BA_ "SigType" SG_ 2566838521 AddressAssignment 1;
BA_ "SPN" SG_ 2566838521 AddressAssignment 2847;
BA_ "SAEDocument" SG_ 2566838521 AddressAssignment "J1939-81";
BA_ "SPN" SG_ 2566838521 ArbitraryAddressCapable 2844;
BA_ "SAEDocument" SG_ 2566838521 ArbitraryAddressCapable "J1939-81";
BA_ "SPN" SG_ 2566838521 IndustryGroup 2846;
BA_ "SAEDocument" SG_ 2566838521 IndustryGroup "NMEA2000";
BA_ "SPN" SG_ 2566838521 VehicleSystemInstance 2843;
BA_ "SAEDocument" SG_ 2566838521 VehicleSystemInstance "J1939-81";
BA_ "SPN" SG_ 2566838521 Function 2841;
BA_ "SAEDocument" SG_ 2566838521 Function "J1939-81";
BA_ "SAEDocument" SG_ 2566838521 VehicleSystem "J1939-81";
BA_ "SPN" SG_ 2566838521 FunctionInstance 2839;
BA_ "SAEDocument" SG_ 2566838521 FunctionInstance "J1939-81";
BA_ "SPN" SG_ 2566838521 ECUInstance 2840;
BA_ "SAEDocument" SG_ 2566838521 ECUInstance "J1939-81";
BA_ "SigType" SG_ 2566838521 ManufacturerCode 1;
BA_ "SPN" SG_ 2566838521 ManufacturerCode 2838;
BA_ "SAEDocument" SG_ 2566838521 ManufacturerCode "NMEA2000";
BA_ "SPN" SG_ 2566838521 IdentityNumber 2837;
BA_ "SAEDocument" SG_ 2566838521 IdentityNumber "J1939-81";
BA_ "SAEDocument" SG_ 2566838521 VehicleSystem5 "J1939-81";
BA_ "SAEDocument" SG_ 2566838521 VehicleSystem4 "J1939-81";
BA_ "SAEDocument" SG_ 2566838521 VehicleSystem3 "J1939-81";
BA_ "SAEDocument" SG_ 2566838521 VehicleSystem2 "J1939-81";
BA_ "SAEDocument" SG_ 2566838521 VehicleSystem1 "J1939-81";
BA_ "SAEDocument" SG_ 2565799678 VehicleSystem1 "J1939-81";
BA_ "SAEDocument" SG_ 2565799678 VehicleSystem2 "J1939-81";
BA_ "SAEDocument" SG_ 2565799678 VehicleSystem3 "J1939-81";
BA_ "SAEDocument" SG_ 2565799678 VehicleSystem4 "J1939-81";
BA_ "SAEDocument" SG_ 2565799678 VehicleSystem5 "J1939-81";
BA_ "SAEDocument" SG_ 2565799678 VehicleSystem "J1939-81";
BA_ "SPN" SG_ 2565799678 IdentityNumber 2837;
BA_ "SAEDocument" SG_ 2565799678 IdentityNumber "J1939-81";
BA_ "SigType" SG_ 2565799678 ManufacturerCode 1;
BA_ "SPN" SG_ 2565799678 ManufacturerCode 2838;
BA_ "SAEDocument" SG_ 2565799678 ManufacturerCode "NMEA2000";
BA_ "SPN" SG_ 2565799678 ECUInstance 2840;
BA_ "SAEDocument" SG_ 2565799678 ECUInstance "J1939-81";
BA_ "SPN" SG_ 2565799678 FunctionInstance 2839;
BA_ "SAEDocument" SG_ 2565799678 FunctionInstance "J1939-81";
BA_ "SPN" SG_ 2565799678 Function 2841;
BA_ "SAEDocument" SG_ 2565799678 Function "J1939-81";
BA_ "SPN" SG_ 2565799678 VehicleSystemInstance 2843;
BA_ "SAEDocument" SG_ 2565799678 VehicleSystemInstance "J1939-81";
BA_ "SPN" SG_ 2565799678 IndustryGroup 2846;
BA_ "SAEDocument" SG_ 2565799678 IndustryGroup "NMEA2000";
BA_ "SPN" SG_ 2565799678 ArbitraryAddressCapable 2844;
BA_ "SAEDocument" SG_ 2565799678 ArbitraryAddressCapable "J1939-81";
BA_ "SigType" SG_ 2566838912 NmbrOfSftwreIdentificationFields 1;
BA_ "SPN" SG_ 2566838912 NmbrOfSftwreIdentificationFields 965;
BA_ "SAEDocument" SG_ 2566838912 NmbrOfSftwreIdentificationFields "J1939-71";
BA_ "SigType" SG_ 2566838912 SoftwareIdentification 1;
BA_ "SPN" SG_ 2566838912 SoftwareIdentification 234;
BA_ "SAEDocument" SG_ 2566838912 SoftwareIdentification "J1939-71";
BA_ "SigType" SG_ 2566768000 ECUType 1;
BA_ "SPN" SG_ 2566768000 ECUType 2904;
BA_ "SAEDocument" SG_ 2566768000 ECUType "J1939-71";
BA_ "SigType" SG_ 2566768000 ECULocation 1;
BA_ "SPN" SG_ 2566768000 ECULocation 2903;
BA_ "SAEDocument" SG_ 2566768000 ECULocation "J1939-71";
BA_ "SigType" SG_ 2566768000 ECUSerialNumber 1;
BA_ "SPN" SG_ 2566768000 ECUSerialNumber 2902;
BA_ "SAEDocument" SG_ 2566768000 ECUSerialNumber "J1939-71";
BA_ "SigType" SG_ 2566768000 ECUPartNumber 1;
BA_ "SPN" SG_ 2566768000 ECUPartNumber 2901;
BA_ "SAEDocument" SG_ 2566768000 ECUPartNumber "J1939-71";
BA_ "SPN" SG_ 2565799673 ArbitraryAddressCapable 2844;
BA_ "SAEDocument" SG_ 2565799673 ArbitraryAddressCapable "J1939-81";
BA_ "SPN" SG_ 2565799673 IndustryGroup 2846;
BA_ "SAEDocument" SG_ 2565799673 IndustryGroup "NMEA2000";
BA_ "SPN" SG_ 2565799673 VehicleSystemInstance 2843;
BA_ "SAEDocument" SG_ 2565799673 VehicleSystemInstance "J1939-81";
BA_ "SPN" SG_ 2565799673 Function 2841;
BA_ "SAEDocument" SG_ 2565799673 Function "J1939-81";
BA_ "SPN" SG_ 2565799673 FunctionInstance 2839;
BA_ "SAEDocument" SG_ 2565799673 FunctionInstance "J1939-81";
BA_ "SPN" SG_ 2565799673 ECUInstance 2840;
BA_ "SAEDocument" SG_ 2565799673 ECUInstance "J1939-81";
BA_ "SigType" SG_ 2565799673 ManufacturerCode 1;
BA_ "SPN" SG_ 2565799673 ManufacturerCode 2838;
BA_ "SAEDocument" SG_ 2565799673 ManufacturerCode "NMEA2000";
BA_ "SPN" SG_ 2565799673 IdentityNumber 2837;
BA_ "SAEDocument" SG_ 2565799673 IdentityNumber "J1939-81";
BA_ "SAEDocument" SG_ 2565799673 VehicleSystem "J1939-81";
BA_ "SAEDocument" SG_ 2565799673 VehicleSystem5 "J1939-81";
BA_ "SAEDocument" SG_ 2565799673 VehicleSystem4 "J1939-81";
BA_ "SAEDocument" SG_ 2565799673 VehicleSystem3 "J1939-81";
BA_ "SAEDocument" SG_ 2565799673 VehicleSystem2 "J1939-81";
BA_ "SAEDocument" SG_ 2565799673 VehicleSystem1 "J1939-81";
BA_ "SPN" SG_ 2565799552 ArbitraryAddressCapable 2844;
BA_ "SAEDocument" SG_ 2565799552 ArbitraryAddressCapable "J1939-81";
BA_ "SPN" SG_ 2565799552 IndustryGroup 2846;
BA_ "SAEDocument" SG_ 2565799552 IndustryGroup "NMEA2000";
BA_ "SPN" SG_ 2565799552 VehicleSystemInstance 2843;
BA_ "SAEDocument" SG_ 2565799552 VehicleSystemInstance "J1939-81";
BA_ "SPN" SG_ 2565799552 Function 2841;
BA_ "SAEDocument" SG_ 2565799552 Function "J1939-81";
BA_ "SPN" SG_ 2565799552 FunctionInstance 2839;
BA_ "SAEDocument" SG_ 2565799552 FunctionInstance "J1939-81";
BA_ "SPN" SG_ 2565799552 ECUInstance 2840;
BA_ "SAEDocument" SG_ 2565799552 ECUInstance "J1939-81";
BA_ "SigType" SG_ 2565799552 ManufacturerCode 1;
BA_ "SPN" SG_ 2565799552 ManufacturerCode 2838;
BA_ "SAEDocument" SG_ 2565799552 ManufacturerCode "NMEA2000";
BA_ "SPN" SG_ 2565799552 IdentityNumber 2837;
BA_ "SAEDocument" SG_ 2565799552 IdentityNumber "J1939-81";
BA_ "SAEDocument" SG_ 2565799552 VehicleSystem "J1939-81";
BA_ "SAEDocument" SG_ 2565799552 VehicleSystem5 "J1939-81";
BA_ "SAEDocument" SG_ 2565799552 VehicleSystem4 "J1939-81";
BA_ "SAEDocument" SG_ 2565799552 VehicleSystem3 "J1939-81";
BA_ "SAEDocument" SG_ 2565799552 VehicleSystem2 "J1939-81";
BA_ "SAEDocument" SG_ 2565799552 VehicleSystem1 "J1939-81";
BA_ "SPN" SG_ 2632712064 SequenceNumber 2572;
BA_ "SAEDocument" SG_ 2632712064 SequenceNumber "J1939-21";
BA_ "SAEDocument" SG_ 2632777600 TotalNumberOfPacketsEoMA "J1939-21";
BA_ "SAEDocument" SG_ 2632777600 TotalMessageSizeEoMA "J1939-21";
BA_ "SAEDocument" SG_ 2632777600 TotalMessageSizeBAM "J1939-21";
BA_ "SAEDocument" SG_ 2632777600 TotalNumberOfPacketsBAM "J1939-21";
BA_ "SPN" SG_ 2632777600 ConnectionAbortReason 2570;
BA_ "SAEDocument" SG_ 2632777600 ConnectionAbortReason "J1939-21";
BA_ "SPN" SG_ 2632777600 NextPacketNumberToBeSent 2562;
BA_ "SAEDocument" SG_ 2632777600 NextPacketNumberToBeSent "J1939-21";
BA_ "SPN" SG_ 2632777600 NumberOfPacketsThatCanBeSent 2561;
BA_ "SAEDocument" SG_ 2632777600 NumberOfPacketsThatCanBeSent "J1939-21";
BA_ "SigType" SG_ 2632777600 PGNumber 6;
BA_ "SPN" SG_ 2632777600 PGNumber 2560;
BA_ "SAEDocument" SG_ 2632777600 PGNumber "J1939-21";
BA_ "SPN" SG_ 2632777600 MaximumNumberOfPackets 2559;
BA_ "SAEDocument" SG_ 2632777600 MaximumNumberOfPackets "J1939-21";
BA_ "SPN" SG_ 2632777600 TotalNumberOfPackets 2558;
BA_ "SAEDocument" SG_ 2632777600 TotalNumberOfPackets "J1939-21";
BA_ "SPN" SG_ 2632777600 TotalMessageSize 2557;
BA_ "SAEDocument" SG_ 2632777600 TotalMessageSize "J1939-21";
BA_ "SPN" SG_ 2632777600 ControlByte 2556;
BA_ "SAEDocument" SG_ 2632777600 ControlByte "J1939-21";
BA_ "SigType" SG_ 2560818942 DTCTimeUntilDerate 1;
BA_ "SPN" SG_ 2560818942 DTCTimeUntilDerate 4123;
BA_ "SAEDocument" SG_ 2560818942 DTCTimeUntilDerate "J1939_73";
BA_ "SigType" SG_ 2560818942 DTCTotalPreviouslyActiveTime 1;
BA_ "SPN" SG_ 2560818942 DTCTotalPreviouslyActiveTime 4122;
BA_ "SAEDocument" SG_ 2560818942 DTCTotalPreviouslyActiveTime "J1939_73";
BA_ "SigType" SG_ 2560818942 DTCTotalActiveTime 1;
BA_ "SPN" SG_ 2560818942 DTCTotalActiveTime 4121;
BA_ "SAEDocument" SG_ 2560818942 DTCTotalActiveTime "J1939_73";
BA_ "SPN" SG_ 2560818942 FailureModeIdentifier1 1215;
BA_ "SAEDocument" SG_ 2560818942 FailureModeIdentifier1 "J1939-73";
BA_ "SAEDocument" SG_ 2560818942 SPN1High "J1939-73";
BA_ "SPN" SG_ 2560818942 SPN1 1214;
BA_ "SAEDocument" SG_ 2560818942 SPN1 "J1939-73";
BA_ "SystemSignalLongSymbol" SG_ 2566764798 NOxConvertingCatalystAdsorberCom "NOxConvertingCatalystAdsorberCompleted";
BA_ "SystemSignalLongSymbol" SG_ 2566764798 NOxConvertingCatalystAdsorberEna "NOxConvertingCatalystAdsorberEnabled";
BA_ "SystemSignalLongSymbol" SG_ 2566764798 BoostPressureControlSystemComple "BoostPressureControlSystemCompleted";
BA_ "SystemSignalLongSymbol" SG_ 2566764798 BoostPressureControlSystemEnable "BoostPressureControlSystemEnabled";
BA_ "SAEDocument" SG_ 2566764798 MisfireMonitoringComplete "J1939-73";
BA_ "SAEDocument" SG_ 2566764798 MisfireMonitoringEnabled "J1939-73";
BA_ "SAEDocument" SG_ 2566764798 FuelSystemMonitoringEnabled "J1939-73";
BA_ "SAEDocument" SG_ 2566764798 ComprehensiveComptMonComplete "J1939-73";
BA_ "SAEDocument" SG_ 2566764798 ComprehensiveCompMonEnabled "J1939-73";
BA_ "SAEDocument" SG_ 2566764798 SecondAirSystemMonComplete "J1939-73";
BA_ "SAEDocument" SG_ 2566764798 SecondAirSystemMonEnabled "J1939-73";
BA_ "SAEDocument" SG_ 2566764798 OxygenSensorMonComplete "J1939-73";
BA_ "SAEDocument" SG_ 2566764798 OxygenSensorMonEnabled "J1939-73";
BA_ "SAEDocument" SG_ 2566764798 OxygenSensorHeaterMonComplete "J1939-73";
BA_ "SAEDocument" SG_ 2566764798 OxygenSensorHeaterMonEnabled "J1939-73";
BA_ "SAEDocument" SG_ 2566764798 HeatedCatalystMonComplete "J1939-73";
BA_ "SAEDocument" SG_ 2566764798 HeatedCatalystMonEnabled "J1939-73";
BA_ "SAEDocument" SG_ 2566764798 EvaporativeSystemMonComplete "J1939-73";
BA_ "SAEDocument" SG_ 2566764798 EvaporativeSystemMonEnabled "J1939-73";
BA_ "SAEDocument" SG_ 2566764798 EGRSystemMonitoringComplete "J1939-73";
BA_ "SAEDocument" SG_ 2566764798 EGRSystemMonitoringEnabled "J1939-73";
BA_ "SAEDocument" SG_ 2566764798 ColdStartAidSystemMonComplete "J1939-73";
BA_ "SAEDocument" SG_ 2566764798 ColdStartAidSystemMonEnabled "J1939-73";
BA_ "SAEDocument" SG_ 2566764798 CatalystMonComplete "J1939-73";
BA_ "SAEDocument" SG_ 2566764798 CatalystMonEnabled "J1939-73";
BA_ "SAEDocument" SG_ 2566764798 ACSystemRefrigerantMonComplete "J1939-73";
BA_ "SAEDocument" SG_ 2566764798 ACSystemRefrigerantMonEnabled "J1939-73";
BA_ "SAEDocument" SG_ 2566764798 FuelSystemMonitoringComplete "J1939-73";
BA_ "SPN" SG_ 2566764798 NumOfWarmUpsSinceDTCsCleared 3302;
BA_ "SAEDocument" SG_ 2566764798 NumOfWarmUpsSinceDTCsCleared "J1939-73";
BA_ "SPN" SG_ 2566764798 TimeSinceEngineStart 3301;
BA_ "SAEDocument" SG_ 2566764798 TimeSinceEngineStart "J1939-73";
BA_ "SAEDocument" SG_ 2564095742 SecurityEntityLengthHigh "J1939-73";
BA_ "SPN" SG_ 2564095742 SecurityEntityType 1479;
BA_ "SAEDocument" SG_ 2564095742 SecurityEntityType "J1939-73";
BA_ "SPN" SG_ 2564095742 SecurityEntityLength 1596;
BA_ "SAEDocument" SG_ 2564095742 SecurityEntityLength "J1939-73";
BA_ "SigType" SG_ 2566839038 NmbrOfSftwreIdentificationFields 1;
BA_ "SPN" SG_ 2566839038 NmbrOfSftwreIdentificationFields 965;
BA_ "SAEDocument" SG_ 2566839038 NmbrOfSftwreIdentificationFields "J1939-71";
BA_ "SigType" SG_ 2566839038 SoftwareIdentification 1;
BA_ "SPN" SG_ 2566839038 SoftwareIdentification 234;
BA_ "SAEDocument" SG_ 2566839038 SoftwareIdentification "J1939-71";
BA_ "SigType" SG_ 2566768126 ECUType 1;
BA_ "SPN" SG_ 2566768126 ECUType 2904;
BA_ "SAEDocument" SG_ 2566768126 ECUType "J1939-71";
BA_ "SigType" SG_ 2566768126 ECULocation 1;
BA_ "SPN" SG_ 2566768126 ECULocation 2903;
BA_ "SAEDocument" SG_ 2566768126 ECULocation "J1939-71";
BA_ "SigType" SG_ 2566768126 ECUSerialNumber 1;
BA_ "SPN" SG_ 2566768126 ECUSerialNumber 2902;
BA_ "SAEDocument" SG_ 2566768126 ECUSerialNumber "J1939-71";
BA_ "SigType" SG_ 2566768126 ECUPartNumber 1;
BA_ "SPN" SG_ 2566768126 ECUPartNumber 2901;
BA_ "SAEDocument" SG_ 2566768126 ECUPartNumber "J1939-71";
BA_ "SigType" SG_ 2566742270 FailureSpecificB1Counter 1;
BA_ "SPN" SG_ 2566742270 FailureSpecificB1Counter 4147;
BA_ "SAEDocument" SG_ 2566742270 FailureSpecificB1Counter "J1939_73";
BA_ "SPN" SG_ 2566742270 FailureModeIdentifier1 1215;
BA_ "SAEDocument" SG_ 2566742270 FailureModeIdentifier1 "J1939-73";
BA_ "SAEDocument" SG_ 2566742270 SPN1High "J1939-73";
BA_ "SPN" SG_ 2566742270 SPN1 1214;
BA_ "SAEDocument" SG_ 2566742270 SPN1 "J1939-73";
BA_ "SigType" SG_ 2566742526 SysGreatestB1Counter 1;
BA_ "SPN" SG_ 2566742526 SysGreatestB1Counter 4146;
BA_ "SAEDocument" SG_ 2566742526 SysGreatestB1Counter "J1939_73";
BA_ "SigType" SG_ 2566742526 SysCumulativeContinuousMITime 1;
BA_ "SPN" SG_ 2566742526 SysCumulativeContinuousMITime 4145;
BA_ "SAEDocument" SG_ 2566742526 SysCumulativeContinuousMITime "J1939_73";
BA_ "SigType" SG_ 2566742782 RegulationDescription 8;
BA_ "SPN" SG_ 2566742782 RegulationDescription 4144;
BA_ "SAEDocument" SG_ 2566742782 RegulationDescription "J1939_73";
BA_ "SigType" SG_ 2566743038 SysIncompleteMonitorCount 1;
BA_ "SPN" SG_ 2566743038 SysIncompleteMonitorCount 4143;
BA_ "SAEDocument" SG_ 2566743038 SysIncompleteMonitorCount "J1939_73";
BA_ "SPN" SG_ 2566743038 SysMalIndActivationMode 4142;
BA_ "SAEDocument" SG_ 2566743038 SysMalIndActivationMode "J1939_73";
BA_ "SigType" SG_ 2566743038 SysMalIndDisplayStrategy 4;
BA_ "SPN" SG_ 2566743038 SysMalIndDisplayStrategy 4141;
BA_ "SAEDocument" SG_ 2566743038 SysMalIndDisplayStrategy "J1939_73";
BA_ "SigType" SG_ 2566743038 SysContinuousMalfunctionInd 4;
BA_ "SPN" SG_ 2566743038 SysContinuousMalfunctionInd 4140;
BA_ "SAEDocument" SG_ 2566743038 SysContinuousMalfunctionInd "J1939_73";
BA_ "SigType" SG_ 2566743038 SysNonRoadworthyCompCount 1;
BA_ "SPN" SG_ 2566743038 SysNonRoadworthyCompCount 4139;
BA_ "SAEDocument" SG_ 2566743038 SysNonRoadworthyCompCount "J1939_73";
BA_ "SigType" SG_ 2566743294 VehicleCurrentMIAccumTime 1;
BA_ "SPN" SG_ 2566743294 VehicleCurrentMIAccumTime 4138;
BA_ "SAEDocument" SG_ 2566743294 VehicleCurrentMIAccumTime "J1939_73";
BA_ "SigType" SG_ 2566743294 VehicleIncompleteMonitorCount 1;
BA_ "SPN" SG_ 2566743294 VehicleIncompleteMonitorCount 4137;
BA_ "SAEDocument" SG_ 2566743294 VehicleIncompleteMonitorCount "J1939_73";
BA_ "SigType" SG_ 2566743294 VehicleMalfunctionIndActMode 4;
BA_ "SPN" SG_ 2566743294 VehicleMalfunctionIndActMode 4136;
BA_ "SAEDocument" SG_ 2566743294 VehicleMalfunctionIndActMode "J1939_73";
BA_ "SigType" SG_ 2566743294 VehicleMalfunctionIndStrategy 4;
BA_ "SPN" SG_ 2566743294 VehicleMalfunctionIndStrategy 4135;
BA_ "SAEDocument" SG_ 2566743294 VehicleMalfunctionIndStrategy "J1939_73";
BA_ "SigType" SG_ 2566743294 VehicleContinuousMalfunctionInd 4;
BA_ "SPN" SG_ 2566743294 VehicleContinuousMalfunctionInd 4134;
BA_ "SAEDocument" SG_ 2566743294 VehicleContinuousMalfunctionInd "J1939_73";
BA_ "SigType" SG_ 2566743294 VehicleNonRoadworthyCompCount 1;
BA_ "SPN" SG_ 2566743294 VehicleNonRoadworthyCompCount 4133;
BA_ "SAEDocument" SG_ 2566743294 VehicleNonRoadworthyCompCount "J1939_73";
BA_ "SigType" SG_ 2560687870 PMNTEDeficiencyAreaStatus 4;
BA_ "SPN" SG_ 2560687870 PMNTEDeficiencyAreaStatus 4132;
BA_ "SAEDocument" SG_ 2560687870 PMNTEDeficiencyAreaStatus "J1939_73";
BA_ "SigType" SG_ 2560687870 MnfcPMNTECarveOutAreaStatus 4;
BA_ "SPN" SG_ 2560687870 MnfcPMNTECarveOutAreaStatus 4131;
BA_ "SAEDocument" SG_ 2560687870 MnfcPMNTECarveOutAreaStatus "J1939_73";
BA_ "SigType" SG_ 2560687870 PMNTEControlAreaStatus 4;
BA_ "SPN" SG_ 2560687870 PMNTEControlAreaStatus 4130;
BA_ "SAEDocument" SG_ 2560687870 PMNTEControlAreaStatus "J1939_73";
BA_ "SigType" SG_ 2560687870 NOxNTEDeficiencyAreaStatus 4;
BA_ "SPN" SG_ 2560687870 NOxNTEDeficiencyAreaStatus 4129;
BA_ "SAEDocument" SG_ 2560687870 NOxNTEDeficiencyAreaStatus "J1939_73";
BA_ "SigType" SG_ 2560687870 MnfcNOxNTECarveOutAreaStatus 4;
BA_ "SPN" SG_ 2560687870 MnfcNOxNTECarveOutAreaStatus 4128;
BA_ "SAEDocument" SG_ 2560687870 MnfcNOxNTECarveOutAreaStatus "J1939_73";
BA_ "SigType" SG_ 2560687870 NOxNTEControlAreaStatus 4;
BA_ "SPN" SG_ 2560687870 NOxNTEControlAreaStatus 4127;
BA_ "SAEDocument" SG_ 2560687870 NOxNTEControlAreaStatus "J1939_73";
BA_ "SigType" SG_ 2292317950 AECDEngineHours1Timer2 1;
BA_ "SPN" SG_ 2292317950 AECDEngineHours1Timer2 4126;
BA_ "SAEDocument" SG_ 2292317950 AECDEngineHours1Timer2 "J1939_73";
BA_ "SigType" SG_ 2292317950 AECDEngineHours1Timer1 1;
BA_ "SPN" SG_ 2292317950 AECDEngineHours1Timer1 4125;
BA_ "SAEDocument" SG_ 2292317950 AECDEngineHours1Timer1 "J1939_73";
BA_ "SigType" SG_ 2292317950 AECDNumber1 1;
BA_ "SPN" SG_ 2292317950 AECDNumber1 4124;
BA_ "SAEDocument" SG_ 2292317950 AECDNumber1 "J1939_73";
BA_ "SigType" SG_ 2560884478 DTCWarnLampSupportStatus 4;
BA_ "SPN" SG_ 2560884478 DTCWarnLampSupportStatus 4115;
BA_ "SAEDocument" SG_ 2560884478 DTCWarnLampSupportStatus "J1939_73";
BA_ "SigType" SG_ 2560884478 DTCWarnLampSupportFlash 4;
BA_ "SPN" SG_ 2560884478 DTCWarnLampSupportFlash 4119;
BA_ "SAEDocument" SG_ 2560884478 DTCWarnLampSupportFlash "J1939_73";
BA_ "SigType" SG_ 2560884478 DTCStopLampSupportStatus 4;
BA_ "SPN" SG_ 2560884478 DTCStopLampSupportStatus 4114;
BA_ "SAEDocument" SG_ 2560884478 DTCStopLampSupportStatus "J1939_73";
BA_ "SigType" SG_ 2560884478 DTCStopLampSupportFlash 4;
BA_ "SPN" SG_ 2560884478 DTCStopLampSupportFlash 4118;
BA_ "SAEDocument" SG_ 2560884478 DTCStopLampSupportFlash "J1939_73";
BA_ "SigType" SG_ 2560884478 DTCProtectLampSupportStatus 4;
BA_ "SPN" SG_ 2560884478 DTCProtectLampSupportStatus 4116;
BA_ "SAEDocument" SG_ 2560884478 DTCProtectLampSupportStatus "J1939_73";
BA_ "SigType" SG_ 2560884478 DTCProtectLampSupportFlash 4;
BA_ "SPN" SG_ 2560884478 DTCProtectLampSupportFlash 4120;
BA_ "SAEDocument" SG_ 2560884478 DTCProtectLampSupportFlash "J1939_73";
BA_ "SPN" SG_ 2560884478 DTCMilSupportStatus 4113;
BA_ "SAEDocument" SG_ 2560884478 DTCMilSupportStatus "J1939_73";
BA_ "SPN" SG_ 2560884478 DTCMilSupportFlash 4117;
BA_ "SAEDocument" SG_ 2560884478 DTCMilSupportFlash "J1939_73";
BA_ "SigType" SG_ 2560884478 DTC1 7;
BA_ "SAEDocument" SG_ 2560884478 DTC1 "J1939-73";
BA_ "SigType" SG_ 2560950014 TestLimitMinimum 1;
BA_ "SPN" SG_ 2560950014 TestLimitMinimum 4112;
BA_ "SAEDocument" SG_ 2560950014 TestLimitMinimum "J1939_73";
BA_ "SigType" SG_ 2560950014 TestLimitMaximum 1;
BA_ "SPN" SG_ 2560950014 TestLimitMaximum 4111;
BA_ "SAEDocument" SG_ 2560950014 TestLimitMaximum "J1939_73";
BA_ "SigType" SG_ 2560950014 TestValue 1;
BA_ "SPN" SG_ 2560950014 TestValue 4110;
BA_ "SAEDocument" SG_ 2560950014 TestValue "J1939_73";
BA_ "SigType" SG_ 2560950014 SlotId 1;
BA_ "SPN" SG_ 2560950014 SlotId 4109;
BA_ "SAEDocument" SG_ 2560950014 SlotId "J1939_73";
BA_ "SAEDocument" SG_ 2560950014 TestIdentifier "J1939_73";
BA_ "SPN" SG_ 2560950014 FailureModeIdentifier1 1215;
BA_ "SAEDocument" SG_ 2560950014 FailureModeIdentifier1 "J1939-73";
BA_ "SAEDocument" SG_ 2560950014 SPN1High "J1939-73";
BA_ "SPN" SG_ 2560950014 SPN1 1214;
BA_ "SAEDocument" SG_ 2560950014 SPN1 "J1939-73";
BA_ "SigType" SG_ 2566836478 TestLimitMinimum 1;
BA_ "SPN" SG_ 2566836478 TestLimitMinimum 1228;
BA_ "SAEDocument" SG_ 2566836478 TestLimitMinimum "J1939-73";
BA_ "SigType" SG_ 2566836478 TestLimitMaximum 1;
BA_ "SPN" SG_ 2566836478 TestLimitMaximum 1227;
BA_ "SAEDocument" SG_ 2566836478 TestLimitMaximum "J1939-73";
BA_ "SigType" SG_ 2566836478 TestValue 1;
BA_ "SPN" SG_ 2566836478 TestValue 1226;
BA_ "SAEDocument" SG_ 2566836478 TestValue "J1939-73";
BA_ "SigType" SG_ 2566836478 TestType 1;
BA_ "GenSigStartValue" SG_ 2566836478 TestType 1;
BA_ "SPN" SG_ 2566836478 TestType 1225;
BA_ "SAEDocument" SG_ 2566836478 TestType "J1939-73";
BA_ "SigType" SG_ 2566836478 TestIdentifier 1;
BA_ "GenSigStartValue" SG_ 2566836478 TestIdentifier 1;
BA_ "SPN" SG_ 2566836478 TestIdentifier 1224;
BA_ "SAEDocument" SG_ 2566836478 TestIdentifier "J1939-73";
BA_ "SAEDocument" SG_ 2565078782 SPN1High "J1939-73";
BA_ "SPN" SG_ 2565078782 SPN1 1214;
BA_ "SAEDocument" SG_ 2565078782 SPN1 "J1939-73";
BA_ "SigType" SG_ 2565078782 TestIdentifier 1;
BA_ "GenSigStartValue" SG_ 2565078782 TestIdentifier 1;
BA_ "SPN" SG_ 2565078782 TestIdentifier 1224;
BA_ "SAEDocument" SG_ 2565078782 TestIdentifier "J1939-73";
BA_ "SPN" SG_ 2565078782 FailureModeIdentifier1 1215;
BA_ "SAEDocument" SG_ 2565078782 FailureModeIdentifier1 "J1939-73";
BA_ "SigType" SG_ 2566836222 FlashRedStopLamp 4;
BA_ "SPN" SG_ 2566836222 FlashRedStopLamp 3039;
BA_ "SAEDocument" SG_ 2566836222 FlashRedStopLamp "J1939-73";
BA_ "SigType" SG_ 2566836222 FlashProtectLamp 4;
BA_ "SPN" SG_ 2566836222 FlashProtectLamp 3041;
BA_ "SAEDocument" SG_ 2566836222 FlashProtectLamp "J1939-73";
BA_ "SigType" SG_ 2566836222 FlashMalfuncIndicatorLamp 4;
BA_ "SPN" SG_ 2566836222 FlashMalfuncIndicatorLamp 3038;
BA_ "SAEDocument" SG_ 2566836222 FlashMalfuncIndicatorLamp "J1939-73";
BA_ "SigType" SG_ 2566836222 FlashAmberWarningLamp 4;
BA_ "SPN" SG_ 2566836222 FlashAmberWarningLamp 3040;
BA_ "SAEDocument" SG_ 2566836222 FlashAmberWarningLamp "J1939-73";
BA_ "SigType" SG_ 2566836222 MalfunctionIndicatorLampStatus 4;
BA_ "SPN" SG_ 2566836222 MalfunctionIndicatorLampStatus 1213;
BA_ "SAEDocument" SG_ 2566836222 MalfunctionIndicatorLampStatus "J1939-73";
BA_ "SigType" SG_ 2566836222 RedStopLampState 4;
BA_ "SPN" SG_ 2566836222 RedStopLampState 623;
BA_ "SAEDocument" SG_ 2566836222 RedStopLampState "J1939-73";
BA_ "SigType" SG_ 2566836222 AmberWarningLampStatus 4;
BA_ "SPN" SG_ 2566836222 AmberWarningLampStatus 624;
BA_ "SAEDocument" SG_ 2566836222 AmberWarningLampStatus "J1939-73";
BA_ "SigType" SG_ 2566836222 ProtectLampStatus 4;
BA_ "SPN" SG_ 2566836222 ProtectLampStatus 987;
BA_ "SAEDocument" SG_ 2566836222 ProtectLampStatus "J1939-73";
BA_ "SigType" SG_ 2566836222 DTC5 7;
BA_ "SAEDocument" SG_ 2566836222 DTC5 "J1939-73";
BA_ "SigType" SG_ 2566836222 DTC4 7;
BA_ "SAEDocument" SG_ 2566836222 DTC4 "J1939-73";
BA_ "SigType" SG_ 2566836222 DTC3 7;
BA_ "SAEDocument" SG_ 2566836222 DTC3 "J1939-73";
BA_ "SigType" SG_ 2566836222 DTC2 7;
BA_ "SAEDocument" SG_ 2566836222 DTC2 "J1939-73";
BA_ "SigType" SG_ 2566836222 DTC1 7;
BA_ "SAEDocument" SG_ 2566836222 DTC1 "J1939-73";
BA_ "SystemSignalLongSymbol" SG_ 2566835966 NOxConvertingCatalystAdsorberSta "NOxConvertingCatalystAdsorberStatus";
BA_ "SystemSignalLongSymbol" SG_ 2566835966 BoostPressureControlSystemSuppor "BoostPressureControlSystemSupport";
BA_ "SystemSignalLongSymbol" SG_ 2566835966 NOxConvertingCatalystAdsorberSup "NOxConvertingCatalystAdsorberSupport";
BA_ "SAEDocument" SG_ 2566835966 MisfireMonitoringSupport "J1939-73";
BA_ "SigType" SG_ 2566835966 OBDCompliance 1;
BA_ "SPN" SG_ 2566835966 OBDCompliance 1220;
BA_ "SAEDocument" SG_ 2566835966 OBDCompliance "J1939-73";
BA_ "SigType" SG_ 2566835966 PreviouslyActiveTroubleCodes 1;
BA_ "SPN" SG_ 2566835966 PreviouslyActiveTroubleCodes 1219;
BA_ "SAEDocument" SG_ 2566835966 PreviouslyActiveTroubleCodes "J1939-73";
BA_ "SigType" SG_ 2566835966 ActiveTroubleCodes 1;
BA_ "SPN" SG_ 2566835966 ActiveTroubleCodes 1218;
BA_ "SAEDocument" SG_ 2566835966 ActiveTroubleCodes "J1939-73";
BA_ "SAEDocument" SG_ 2566835966 SecondAirSystemMonStatus "J1939-73";
BA_ "SAEDocument" SG_ 2566835966 EvaporativeSystemMonStatus "J1939-73";
BA_ "SAEDocument" SG_ 2566835966 ACSystemRefrigerantMonStatus "J1939-73";
BA_ "SAEDocument" SG_ 2566835966 OxygenSensorHeaterMonStatus "J1939-73";
BA_ "SAEDocument" SG_ 2566835966 OxygenSensorMonStatus "J1939-73";
BA_ "SAEDocument" SG_ 2566835966 EGRSystemMonitoringStatus "J1939-73";
BA_ "SAEDocument" SG_ 2566835966 CatalystMonStatus "J1939-73";
BA_ "SAEDocument" SG_ 2566835966 ColdStartAidSystemMonStatus "J1939-73";
BA_ "SAEDocument" SG_ 2566835966 HeatedCatalystMonStatus "J1939-73";
BA_ "SAEDocument" SG_ 2566835966 CatalystMonSupp "J1939-73";
BA_ "SAEDocument" SG_ 2566835966 ColdStartAidSystemMonSupp "J1939-73";
BA_ "SAEDocument" SG_ 2566835966 HeatedCatalystMonSupp "J1939-73";
BA_ "SAEDocument" SG_ 2566835966 EvaporativeSystemMonSupp "J1939-73";
BA_ "SAEDocument" SG_ 2566835966 SecondAirSystemMonSupp "J1939-73";
BA_ "SAEDocument" SG_ 2566835966 ACSystemRefrigerantMonSupp "J1939-73";
BA_ "SAEDocument" SG_ 2566835966 OxygenSensorMonSupp "J1939-73";
BA_ "SAEDocument" SG_ 2566835966 OxygenSensorHeaterMonSupp "J1939-73";
BA_ "SAEDocument" SG_ 2566835966 EGRSystemMonitoringSupp "J1939-73";
BA_ "SAEDocument" SG_ 2566835966 MisfireMonitoringStatus "J1939-73";
BA_ "SAEDocument" SG_ 2566835966 ComprehensiveCompMonStatus "J1939-73";
BA_ "SAEDocument" SG_ 2566835966 FuelSystemMonitoringStatus "J1939-73";
BA_ "SAEDocument" SG_ 2566835966 ComprehensiveComponentMonSupp "J1939-73";
BA_ "SAEDocument" SG_ 2566835966 FuelSystemMonitoringSupport "J1939-73";
BA_ "SigType" SG_ 2566835710 EngIntakeManifold1Press 1;
BA_ "SPN" SG_ 2566835710 EngIntakeManifold1Press 102;
BA_ "SAEDocument" SG_ 2566835710 EngIntakeManifold1Press "J1939-71";
BA_ "SPN" SG_ 2566835710 FreezeFrameLength 1217;
BA_ "SAEDocument" SG_ 2566835710 FreezeFrameLength "J1939-73";
BA_ "SigType" SG_ 2566835710 EngSpeed 1;
BA_ "SPN" SG_ 2566835710 EngSpeed 190;
BA_ "SAEDocument" SG_ 2566835710 EngSpeed "J1939-71";
BA_ "SPN" SG_ 2566835710 EngTorqueMode 899;
BA_ "SAEDocument" SG_ 2566835710 EngTorqueMode "J1939-71";
BA_ "SigType" SG_ 2566835710 WheelBasedVehicleSpeed 1;
BA_ "SPN" SG_ 2566835710 WheelBasedVehicleSpeed 84;
BA_ "SAEDocument" SG_ 2566835710 WheelBasedVehicleSpeed "J1939-71";
BA_ "SPN" SG_ 2566835710 EngPercentLoadAtCurrentSpeed 92;
BA_ "SAEDocument" SG_ 2566835710 EngPercentLoadAtCurrentSpeed "J1939-71";
BA_ "SigType" SG_ 2566835710 EngCoolantTemp 1;
BA_ "SPN" SG_ 2566835710 EngCoolantTemp 110;
BA_ "SAEDocument" SG_ 2566835710 EngCoolantTemp "J1939-71";
BA_ "SigType" SG_ 2566835710 DTC1 7;
BA_ "SAEDocument" SG_ 2566835710 DTC1 "J1939-73";
BA_ "SPN" SG_ 2566764542 ExpandedFreezeFrameLength 3149;
BA_ "SAEDocument" SG_ 2566764542 ExpandedFreezeFrameLength "J1939-73";
BA_ "SigType" SG_ 2566764542 DTC1 7;
BA_ "SAEDocument" SG_ 2566764542 DTC1 "J1939-73";
BA_ "SAEDocument" SG_ 2566764286 SPNSupported1High "J1939-73";
BA_ "SAEDocument" SG_ 2566764286 SPNSupportTypeSTR3 "J1939-73";
BA_ "SAEDocument" SG_ 2566764286 SPNSupportTypeSTR2 "J1939-73";
BA_ "SAEDocument" SG_ 2566764286 SPNSupportTypeEFF3 "J1939-73";
BA_ "SAEDocument" SG_ 2566764286 SPNSupportTypeEFF2 "J1939-73";
BA_ "SAEDocument" SG_ 2566764286 SPNSupportTypeDS3 "J1939-73";
BA_ "SAEDocument" SG_ 2566764286 SPNSupportTypeDS2 "J1939-73";
BA_ "SAEDocument" SG_ 2566764286 SPNSupported3High "J1939-73";
BA_ "SAEDocument" SG_ 2566764286 SPNSupported2High "J1939-73";
BA_ "SAEDocument" SG_ 2566764286 SPNSupported3 "J1939-73";
BA_ "SAEDocument" SG_ 2566764286 SPNSupported2 "J1939-73";
BA_ "SAEDocument" SG_ 2566764286 SPNDataLength3 "J1939-73";
BA_ "SAEDocument" SG_ 2566764286 SPNSupportTypeSTR1 "J1939-73";
BA_ "SAEDocument" SG_ 2566764286 SPNSupportTypeDS1 "J1939-73";
BA_ "SAEDocument" SG_ 2566764286 SPNSupportTypeEFF1 "J1939-73";
BA_ "SAEDocument" SG_ 2566764286 SPNDataLength2 "J1939-73";
BA_ "SPN" SG_ 2566764286 SPNDataLength1 4103;
BA_ "SAEDocument" SG_ 2566764286 SPNDataLength1 "J1939-73";
BA_ "SPN" SG_ 2566764286 SPNSupported1 3297;
BA_ "SAEDocument" SG_ 2566764286 SPNSupported1 "J1939-73";
VAL_ 2566838521 IndustryGroup 6 "Reserved for SAE" 7 "Reserved for SAE" 5 "IndustrialProcessCtrlStationary" 4 "Marine" 3 "Construction" 2 "Agricultural and Forestry" 1 "On-Highway" 0 "Global" ;
VAL_ 2566838521 Function 127 "Reserved" 126 "Reserved" 125 "Reserved" 124 "Reserved" 123 "Reserved" 122 "Reserved" 121 "Reserved" 120 "Reserved" 119 "Reserved" 118 "Reserved" 117 "Reserved" 116 "Reserved" 115 "Reserved" 114 "Reserved" 113 "Reserved" 112 "Reserved" 111 "Reserved" 110 "Reserved" 109 "Reserved" 108 "Reserved" 107 "Reserved" 106 "Reserved" 105 "Reserved" 104 "Reserved" 103 "Reserved" 102 "Reserved" 101 "Reserved" 42 "Water Pump Control" 41 "Lighting - Operator Controls" 40 "Seat Control" 39 "Ignition Control Module" 38 "Tire Pressure Control" 37 "Cab Controller" 36 "Pneumatic - System Controller" 35 "Suspension - System Controller" 34 "Hydraulic Pump Controller" 33 "System Monitor" 32 "Headway Controller" 31 "Propulsion Battery Charger" 30 "Management Computer" 29 "Virtual Terminal (in cab)" 28 "Off Vehicle Gateway" 27 "Power TakeOff (Secondary or Front)" 26 "Body Controller" 25 "Network Interconnect ECU" 24 "Vehicle Security" 23 "Vehicle Navigation" 22 "Aerodynamic Control" 21 "Cab Climate Control" 20 "Trip Recorder" 19 "Instrument Cluster" 18 "Suspension - Drive Axle" 17 "Suspension - Steer Axle" 16 "Steering Controller" 15 "Fuel System" 14 "Cruise Control" 13 "Retarder - Driveline" 12 "Retarder - Engine" 11 "Brakes - Drive Axle" 10 "Brakes - Steer Axle" 9 "Brakes - System Controller" 8 "Axle - Drive" 7 "Axle - Steering" 6 "Power TakeOff - (Main or Rear)" 5 "Shift Control/Console" 4 "Battery Pack Monitor" 3 "Transmission" 2 "Electric Propulsion Control" 1 "Auxiliary Power Unit (APU)" 0 "Engine" 100 "Reserved" 99 "Reserved" 98 "Reserved" 97 "Reserved" 96 "Reserved" 95 "Reserved" 94 "Reserved" 93 "Reserved" 92 "Reserved" 91 "Reserved" 90 "Reserved" 89 "Reserved" 88 "Reserved" 87 "Reserved" 86 "Reserved" 85 "Reserved" 84 "Reserved" 83 "Reserved" 82 "Reserved" 81 "Reserved" 80 "Reserved" 79 "Reserved" 78 "Reserved" 77 "Reserved" 76 "Reserved" 75 "Supplemental Fan" 74 "Lubrication System" 73 "Rollover Detection Control" 72 "Coolant Valve Controller" 71 "Transfer Case Control" 70 "Auxiliary Regeneration Device" 69 "Engine Emission Aftertreatement System" 68 "Aftertreatment system gas measurement" 67 "Electrical System Controller" 66 "I/O Controller" 65 "Gas Flow Measurement" 64 "Endurance Braking" 63 "Engine Valve Controller" 62 "On-Board Diagnostic Unit" 61 "File Server/Printer" 60 "Cab Display" 59 "Starter" 58 "Fan Drive Control" 57 "Steering Column Unit" 56 "Communications Unit, Radio" 55 "Communications Unit, Satellite" 54 "Communications Unit, Cellular" 53 "Alternator/Charging System" 52 "Chassis Controller" 51 "Forward-Looking Collision Warning System" 50 "Auxiliary Heater" 49 "Clutch/Converter Control" 48 "Ramp Control" 47 "Information System Controller" 46 "Oil Sensor Unit" 45 "Vehicle Dynamic Stability Control" 44 "Exhaust Emission Control" 43 "Transmission Display" ;
VAL_ 2566838521 VehicleSystem 0 "Non-specific System" 127 "Not Available" ;
VAL_ 2566838521 ManufacturerCode 381 "B&G" 374 "Northern Lights" 373 "Electronic Design" 371 "Delphi" 370 "Heinzmann GmbH & Co. KG" 369 "Power Torque Engineering Ltd" 368 "HANSENHOF_electronic" 367 "Fliegl Agrartechnik" 366 "Viewnyx Corp." 365 "Digi-Star, LLC" 364 "OEM Controls Inc." 363 "BEI Duncan" 362 "Alois Poettinger Maschinenfabrik GmbH" 361 "InMach" 360 "HJS Fahrzeugtechnik GmbH & Co KG" 359 "Ludwig Bergmann GmbH" 358 "Victron Energy BV" 357 "Hardi International A/S" 356 "Fischer Panda Generators, Inc" 355 "Mastervolt International B.V." 354 "Junkkari OY" 353 "Hegemon Electronics, Inc." 352 "SAME DEUTZ-FAHR" 351 "Thrane & Thrane" 350 "Noris Marine Systems GmbH & Co KG" 349 "Suonentiet" 348 "Amazonen Werke H. Dreyer" 347 "Honeywell" 346 "Control Solutions" 345 "Korean Maritime University" 344 "Parvus Corporation" 343 "Baumer Group" 342 "THOMAS MAGNETE GmbH" 341 "Boning GmbH & Co" 340 "Continental AG" 339 "Competence Center ISOBUS e.V." 338 "GRAF-SYTECO" 337 "Carraro S.p.A." 336 "APE s.r.o." 335 "Evo Electric Ltd" 334 "Takata-Petri AG" 333 "Hadley Products Corporation" 332 "HWH Corporation" 331 "Horton, Inc." 330 "Kidde Aerospace and Defense" 329 "Deif A/S" 328 "Qwerty Electronik AB" 252 "Sensor-Technik Wiedemann GmbH" 251 "German Agricultural Society" 250 "Kuhn Group" 249 "Schaltbau GmbH" 233 "Yacht Monitoring Solutions Inc." 232 "TSD Integrated Controls" 1863 "Thomas G. Faria Co." 1862 "Sanshin" 1861 "Vector CANtech" 1860 "MMP" 1859 "Kvasar AB" 1858 "Litton" 1857 "Simrad" 1856 "Trimble" 1855 "Furuno USA" 1854 "Northstar Technologies" 1853 "Japan Radio Co." 1852 "Navionics" 1851 "Raymarine" 1850 "Teleflex" 222 "Generac Power Systems, Inc." 221 "SiE" 220 "Beede Electrical Instrument Company, Inc." 219 "Cat OEM Solutions" 218 "Gits Manufacturing Company" 217 "RM Michaelides Software & Elektronik GmbH" 216 "Paneltronics Inc." 215 "Aetna Engineering/Fireboy-Xintex" 214 "MC elettronica Srl" 213 "CNH Belgium N.V." 212 "Sure Power Industries, Inc." 211 "DNA Group" 210 "Iteris, Inc." 209 "Bell Equip. Co. SA (PTY) LTD" 208 "Drew Technologies, Inc." 207 "Otto Engineering" 206 "port GmbH" 205 "SmarTire Systems Inc" 204 "The Morey Corporation" 203 "MILtronik GmbH" 202 "Curtis Instruments, Inc." 201 "Disenos y Tecnologia S.A." 200 "MGM Brakes" 199 "Actia Corp." 198 "Mystic Valley Communications" 197 "Mechron Power Systems" 196 "LEMKEN GmbH & Co. KG" 195 "General Engine Products" 194 "TriMark Corporation" 193 "Nobletec" 192 "Floscan" 191 "XATA Corporation" 190 "Hella KGaA Hueck & Co." 189 "QUALCOMM" 188 "EMP Corp." 187 "Air-Weigh" 186 "Altronic, Inc." 185 "Beede Electrical Instrument Company" 184 "EIA Electronics" 183 "KDS Controls, Inc." 182 "Vehicle Systems Engineering B.V." 181 "Coretronics, Inc." 180 "Smart Power Systems" 179 "TeeJet Technologies Denmark" 178 "Siemens VDO Automotive AG" 177 "Diagnostic System Associates" 176 "Moritz Aerospace" 175 "Veris Technologies, Inc." 174 "AB Volvo Penta" 173 "Ryeso, Inc." 172 "Yanmar Marine USA" 171 "Wachendorff Elektronik GmbH & Co. KG" 170 "Computronics Corporation Ltd." 169 "Marlin Technologies Inc." 168 "Xantrex" 167 "JLG Industries Inc." 166 "Phoenix International" 165 "CPAC Systems AB" 164 "DaimlerChrysler Off-Highway" 163 "BRP Inc." 162 "Axiomatic Technologies" 161 "Offshore Systems (UK) Limited" 160 "Nido" 159 "NTech Industries Inc." 158 "Firestone Industrial Products Company" 157 "ISSPRO Inc." 156 "ITT Industries - Cannon" 155 "Vetronix Corporation" 154 "Westerbeke Corporation" 153 "Woodward, Industrial Controls Division" 152 "elobau GmbH & Co. KG" 151 "Raven Industries Inc. - Flow Controls Division" 150 "Fleetguard" 149 "Holset" 148 "Blue Water Data, Inc." 147 "Nautibus Electronic GmbH" 146 "Maxima Technologies" 145 "MurCal Controls" 144 "Mercury Marine" 143 "W. Gmeiner GmbH & Co." 142 "TRW Automotive (Commercial Steering Systems)" 141 "Thales Navigation Ltd." 140 "Lowrance Electronics, Inc." 139 "Caterpillar Trimble Control Technologies (CTCT), LLC" 138 "Georg Fritzmeier GmbH & Co. KG" 137 "Maretron" 136 "Komatsu Ltd." 135 "Airmar Technology Corporation" 134 "Iris Technology Ltd." 133 "Bucher Schoerling GmbH" 132 "Mulag-Fahrzeugwerk" 131 "ITT Industries" 130 "Nido - Universal Machines B.V." 129 "OMNEX Control Systems, Inc." 128 "Gerhard Duecker GmbH & Co. KG" 127 "Holland USA" 126 "Driver Tech" 125 "Nevada Automotive Test Center" 124 "Hydac Electronic" 123 "Basler Electric" 122 "FG Wilson (Engineering) Limited" 121 "HED (Hydro Electronic Devices, Inc.)" 120 "RDS Technology Ltd." 119 "IntegriNautics" 118 "Intron GmbH" 117 "HUSCO International" 116 "BEELINE Technologies" 115 "NACCO Materials Handling Group, Inc." 114 "EControls, Inc." 113 "Stress-Tek, Inc." 112 "MECALAC" 111 "Maschinenfabrik Bernhard Krone GmbH" 110 "EPIQ Sensor-Nite" 109 "TeeJet Technologies Denmark" 108 "WTK-Elecktronik GmbH" 107 "Grimme Landmaschinen GmbH & Co. KG" 106 "BAE Systems Controls, Inc." 105 "Kiepe Elektrik GmbH & Co. KG" 104 "Claas Selbstfahrende Erntemaschinen GmbH" 103 "Agrocom GmbH & Co. Agrarsystem KG" 102 "AGCO GmbH & Co." 101 "Sensoria" 100 "VDO Technik AG" 99 "International Transmissions Ltd (ITL)" 98 "Mueller-Elektronik GmbH & Co." 97 "Ag Leader Technology, Inc." 96 "Mech@tronic IT GmbH" 95 "Pacific Insight Electronics Corp." 94 "CNH Global N.V." 93 "Perkins Engines Company Ltd." 92 "Ag-Chem Equipment Co., Inc." 91 "BSG Bodensee Steuergeraete GmbH" 90 "Knorr-Bremse SfN GmbH" 89 "Kverneland Group, Electronics Division" 88 "Satloc Precision GPS" 87 "J.C. Bamford Excavators Ltd (JCB)" 86 "C.E. Niehoff & Company" 85 "Kohler Co." 84 "New Holland UK Limited" 83 "Eaton VORAD Technologies" 82 "Bobcat/Ingersoll-Rand" 81 "Fire Research Corp" 80 "Twin Disc, Inc." 79 "Daimler Benz AG - Engine Division (PBM)" 78 "Frank W. Murphy Manufacturing, Inc." 77 "Deere Power Systems Group" 76 "unused" 75 "Deere & Co. Agricultural Division" 74 "Eaton Axle-Brake Division" 73 "LeTourneau, Inc." 72 "Sisu Corporation" 71 "Vansco Electronics Ltd." 70 "Flex-Coil Limited" 69 "Trimble Navigation" 68 "Scania" 67 "Funk Manufacturing Company" 66 "John Deere Construction Equipment Division" 65 "MAN Nutzfahrzeuge AG" 64 "unused" 63 "ZF Industries Inc." 62 "Wabco" 61 "Volvo Truck Corp." 60 "Volvo Trucks North America Inc." 59 "VES Inc." 58 "SPX Corporation, OTC Division" 57 "Sauer-Danfoss Co." 56 "SAIC" 55 "Ryder System Inc." 54 "Meritor Wabco" 53 "Continental Automotive Systems US, Inc." 52 "Meritor Automotive, Inc." 51 "Robert Bosch GmbH" 50 "Robert Bosch Corp" 49 "RE America Inc." 48 "Pollak Alphabet" 47 "Phillips Semiconductor" 46 "Parasoft Computing Solutions" 45 "PACCAR" 44 "Nippondenso Co. Ltd." 43 "International Truck and Engine Corp. Vehicle Electronics" 42 "International Truck and Engine Corp. Engine Electronics" 41 "Motorola Inc." 40 "Motorola AIEG Inc." 39 "Microfirm Inc." 38 "Micro Processor Systems Inc." 37 "Mack Trucks Inc." 36 "Lucas Ltd." 35 "Kenworth Truck Co." 34 "Kelsey Hayes Co." 33 "John Deere" 32 "Jacobs Vehicle Systems" 31 "J Pollak Corp." 30 "Isuzu Motors Ltd." 29 "Hino Motors Ltd." 28 "Grote Ind. Inc." 27 "GMC" 26 "General Motors Corp., Service Technology Group" 25 "Daimler Trucks North America LLC" 24 "Ford Motor Co., Vehicle Controls" 23 "Ford Motor Co., Heavy Truck" 22 "Ford Motor Co., Electronic Concepts $ Systems" 21 "Echilin Inc., Midland Brake Inc." 20 "Eaton Ltd" 19 "Eaton Corp. Trucking Info Services" 18 "Eaton Corp, Transmission Division" 17 "Eaton Corp. Res & Dev" 16 "Eaton Corp." 15 "Dickey-John Corp." 14 "Detroit Diesel Corporation" 13 "Delco Electronics" 12 "Deere & Company, Precision Farming" 11 "Dearborn Group Inc." 10 "Cummins Engine Co." 9 "Chrysler Corp." 8 "Caterpillar Inc." 7 "Case Corp." 6 "Berifors Electronics AB" 5 "AMP Inc." 4 "Ametek-Dixson" 3 "Ametek, US Gauge Division" 2 "Allison Transmission, GMC" 1 "Allied Signal Inc." 0 "Reserved" 231 "Topcon Positioning Systems, Inc." 230 "Saucon Technologies" 229 "Garmin International Inc." 228 "ZF Marine Electronics" 227 "Lykketronic A/S" 226 "Monaco Coach Corporation" 225 "SKF" 224 "EMMI Network, S.L." 223 "Vaueo Retarder Co., Ltd." 263 "IMMI" 262 "HydraForce, Inc" 261 "Red Dot Corporation" 260 "Reichhardt GmbH" 259 "Jetter AG" 258 "ARAG" 257 "Honda Motor Co., Ltd" 256 "Tyco Electronics AMP" 255 "MEAS France" 254 "GE Sensing" 253 "Mobile Control Systems" 298 "Holley Performance" 297 "Zonar Systems Inc" 296 "micro dynamics GmbH" 295 "BEP Marine" 294 "Grayhill Inc." 293 "Spyder Controls Corp." 292 "IKUSI - Angel Iglesias S.A." 291 "Groeneveld Transport Efficiency BV" 290 "Kuebler GmbH" 289 "Watlow" 288 "Mitsubishi FUSO Truck & Bus Corp." 287 "NTech Industries, Inc" 286 "Coelmo srl" 285 "Sea Recovery Corp" 284 "Mobile Tech Chile" 283 "CWF Hamilton & Co Ltd" 282 "Medallion Instrumentation Systems" 281 "Precision Governors LLC" 311 "Patrick Power Products" 310 "TECNORD srl" 309 "Krauss-Maffei Wegmann GmbH & Co. KG" 308 "Cyntrx" 307 "MAS Technologies" 306 "Sleipner Motor AB" 305 "NovAtel Inc" 304 "EmpirBus AB" 303 "CTS Corporation" 302 "Nissin Kogyo Co., LTD" 301 "Parker Hannifin (UK) Ltd FDE group" 300 "Systron Donner Automotive" 299 "Rauch Landmaschinen GmbH" 280 "Leica Geosystems Pty Ltd" 279 "Geometris LP" 278 "Takata Electronics" 277 "LHP Telematics" 276 "Aqua-Hot Heating Systems" 275 "Navico Egersund AS" 274 "LTW Technology Co., LTD" 273 "Active Research Limited" 272 "Gross Mechanical Laboratories, Inc" 327 "Sonceboz SA" 326 "Akron Brass Company" 325 "ASM Automation Sensorik Messtechnik GmbH" 324 "Snap-on Diagnostics" 323 "Mobileye Vision Technologies Ltd." 322 "MICHENKA s.r.o." 321 "Ultra Electronics, Electrics" 320 "Miedema Landbouwwerktuigenfabriek B.V." 319 "Cadec Global" 318 "SAT Plan" 317 "Navtronics Bvba" 316 "ITT Flow Control" 315 "Icom Incorporated" 314 "CSM GmbH" 313 "Ilmor Engineering, Inc" 312 "Lectronix, Inc." 271 "Cole Hersee" 270 "Tennant" 269 "Saft America Inc.,  Space & Defense Division" 268 "Accurate Technologies" 267 "Red Lion Controls, Inc" 266 "International Thermal Research Ltd" 265 "MTS Sensor Technologie GmbH" 264 "Autolync" 248 "Cooper Standard Automotive Active Systems Group" 247 "ePULSE" 246 "Class 1, Inc" 245 "Capstan Ag Systems, Inc." 244 "Techno-Matic" 243 "eRide, Inc." 242 "Kokusandenki Co. Ltd" 241 "Schneider Automation SAS " 240 "Vanair Mfg" 239 "May & Scofield Ltd" 238 "ZF Friedrichshafen AG" 237 "Agtron Enterprises Inc" 236 "Norac Systems International Inc" 235 "SailorMade Marine Telemetry - Tetra Technology Ltd." 234 "Mondial electronic GmbH" ;
VAL_ 2566838521 VehicleSystem5 127 "Not Available" 0 "Ind. Process Control Stationary" ;
VAL_ 2566838521 VehicleSystem4 100 "Deck/Cargo/Fishing equip. sys" 90 "Environmental (HVAC) Systems" 80 "Instrumentation/General Systems" 70 "Communications Systems" 60 "Navigation Systems" 50 "Propulsion Systems" 40 "Steering Systems" 30 "Power Mgmt and lighting systems" 25 "Gateway" 20 "Safety Systems" 10 "System Tools" 127 "Not Available" 0 "Non-specific System" ;
VAL_ 2566838521 VehicleSystem3 8 "Grader" 7 "Four Wheel Drive Loader" 6 "Forklift" 5 "Excavator" 4 "Crawler" 3 "Backhoe" 2 "Articulated Dump Truck" 1 "Skid Steer Loader" 127 "Not Available" 0 "Non-specific System" ;
VAL_ 2566838521 VehicleSystem2 16 "Skidder" 15 "Earth Work" 14 "Special Crops" 13 "Powered Auxiliary Device" 12 "Farm Yard Operations" 11 "Transport/Trailer" 10 "Irrigation" 9 "Forage" 8 "Root Harvesters" 7 "Harvesters" 6 "Sprayers" 5 "Fertilizers" 4 "Planters/Seeders" 3 "Secondary Tillage" 2 "Tillage" 1 "Tractor" 127 "Not Available" 0 "Non-specific System" ;
VAL_ 2566838521 VehicleSystem1 2 "Trailer" 1 "Tractor" 127 "Not Available" 0 "Non-specific System" ;
VAL_ 2565799678 VehicleSystem1 2 "Trailer" 1 "Tractor" 127 "Not Available" 0 "Non-specific System" ;
VAL_ 2565799678 VehicleSystem2 16 "Skidder" 15 "Earth Work" 14 "Special Crops" 13 "Powered Auxiliary Device" 12 "Farm Yard Operations" 11 "Transport/Trailer" 10 "Irrigation" 9 "Forage" 8 "Root Harvesters" 7 "Harvesters" 6 "Sprayers" 5 "Fertilizers" 4 "Planters/Seeders" 3 "Secondary Tillage" 2 "Tillage" 1 "Tractor" 127 "Not Available" 0 "Non-specific System" ;
VAL_ 2565799678 VehicleSystem3 8 "Grader" 7 "Four Wheel Drive Loader" 6 "Forklift" 5 "Excavator" 4 "Crawler" 3 "Backhoe" 2 "Articulated Dump Truck" 1 "Skid Steer Loader" 127 "Not Available" 0 "Non-specific System" ;
VAL_ 2565799678 VehicleSystem4 100 "Deck/Cargo/Fishing equip. sys" 90 "Environmental (HVAC) Systems" 80 "Instrumentation/General Systems" 70 "Communications Systems" 60 "Navigation Systems" 50 "Propulsion Systems" 40 "Steering Systems" 30 "Power Mgmt and lighting systems" 25 "Gateway" 20 "Safety Systems" 10 "System Tools" 127 "Not Available" 0 "Non-specific System" ;
VAL_ 2565799678 VehicleSystem5 127 "Not Available" 0 "Ind. Process Control Stationary" ;
VAL_ 2565799678 VehicleSystem 0 "Non-specific System" 127 "Not Available" ;
VAL_ 2565799678 ManufacturerCode 381 "B&G" 374 "Northern Lights" 373 "Electronic Design" 371 "Delphi" 370 "Heinzmann GmbH & Co. KG" 369 "Power Torque Engineering Ltd" 368 "HANSENHOF_electronic" 367 "Fliegl Agrartechnik" 366 "Viewnyx Corp." 365 "Digi-Star, LLC" 364 "OEM Controls Inc." 363 "BEI Duncan" 362 "Alois Poettinger Maschinenfabrik GmbH" 361 "InMach" 360 "HJS Fahrzeugtechnik GmbH & Co KG" 359 "Ludwig Bergmann GmbH" 358 "Victron Energy BV" 357 "Hardi International A/S" 356 "Fischer Panda Generators, Inc" 355 "Mastervolt International B.V." 354 "Junkkari OY" 353 "Hegemon Electronics, Inc." 352 "SAME DEUTZ-FAHR" 351 "Thrane & Thrane" 350 "Noris Marine Systems GmbH & Co KG" 349 "Suonentiet" 348 "Amazonen Werke H. Dreyer" 347 "Honeywell" 346 "Control Solutions" 345 "Korean Maritime University" 344 "Parvus Corporation" 343 "Baumer Group" 342 "THOMAS MAGNETE GmbH" 341 "Boning GmbH & Co" 340 "Continental AG" 339 "Competence Center ISOBUS e.V." 338 "GRAF-SYTECO" 337 "Carraro S.p.A." 336 "APE s.r.o." 335 "Evo Electric Ltd" 334 "Takata-Petri AG" 333 "Hadley Products Corporation" 332 "HWH Corporation" 331 "Horton, Inc." 330 "Kidde Aerospace and Defense" 329 "Deif A/S" 328 "Qwerty Electronik AB" 252 "Sensor-Technik Wiedemann GmbH" 251 "German Agricultural Society" 250 "Kuhn Group" 249 "Schaltbau GmbH" 233 "Yacht Monitoring Solutions Inc." 232 "TSD Integrated Controls" 1863 "Thomas G. Faria Co." 1862 "Sanshin" 1861 "Vector CANtech" 1860 "MMP" 1859 "Kvasar AB" 1858 "Litton" 1857 "Simrad" 1856 "Trimble" 1855 "Furuno USA" 1854 "Northstar Technologies" 1853 "Japan Radio Co." 1852 "Navionics" 1851 "Raymarine" 1850 "Teleflex" 222 "Generac Power Systems, Inc." 221 "SiE" 220 "Beede Electrical Instrument Company, Inc." 219 "Cat OEM Solutions" 218 "Gits Manufacturing Company" 217 "RM Michaelides Software & Elektronik GmbH" 216 "Paneltronics Inc." 215 "Aetna Engineering/Fireboy-Xintex" 214 "MC elettronica Srl" 213 "CNH Belgium N.V." 212 "Sure Power Industries, Inc." 211 "DNA Group" 210 "Iteris, Inc." 209 "Bell Equip. Co. SA (PTY) LTD" 208 "Drew Technologies, Inc." 207 "Otto Engineering" 206 "port GmbH" 205 "SmarTire Systems Inc" 204 "The Morey Corporation" 203 "MILtronik GmbH" 202 "Curtis Instruments, Inc." 201 "Disenos y Tecnologia S.A." 200 "MGM Brakes" 199 "Actia Corp." 198 "Mystic Valley Communications" 197 "Mechron Power Systems" 196 "LEMKEN GmbH & Co. KG" 195 "General Engine Products" 194 "TriMark Corporation" 193 "Nobletec" 192 "Floscan" 191 "XATA Corporation" 190 "Hella KGaA Hueck & Co." 189 "QUALCOMM" 188 "EMP Corp." 187 "Air-Weigh" 186 "Altronic, Inc." 185 "Beede Electrical Instrument Company" 184 "EIA Electronics" 183 "KDS Controls, Inc." 182 "Vehicle Systems Engineering B.V." 181 "Coretronics, Inc." 180 "Smart Power Systems" 179 "TeeJet Technologies Denmark" 178 "Siemens VDO Automotive AG" 177 "Diagnostic System Associates" 176 "Moritz Aerospace" 175 "Veris Technologies, Inc." 174 "AB Volvo Penta" 173 "Ryeso, Inc." 172 "Yanmar Marine USA" 171 "Wachendorff Elektronik GmbH & Co. KG" 170 "Computronics Corporation Ltd." 169 "Marlin Technologies Inc." 168 "Xantrex" 167 "JLG Industries Inc." 166 "Phoenix International" 165 "CPAC Systems AB" 164 "DaimlerChrysler Off-Highway" 163 "BRP Inc." 162 "Axiomatic Technologies" 161 "Offshore Systems (UK) Limited" 160 "Nido" 159 "NTech Industries Inc." 158 "Firestone Industrial Products Company" 157 "ISSPRO Inc." 156 "ITT Industries - Cannon" 155 "Vetronix Corporation" 154 "Westerbeke Corporation" 153 "Woodward, Industrial Controls Division" 152 "elobau GmbH & Co. KG" 151 "Raven Industries Inc. - Flow Controls Division" 150 "Fleetguard" 149 "Holset" 148 "Blue Water Data, Inc." 147 "Nautibus Electronic GmbH" 146 "Maxima Technologies" 145 "MurCal Controls" 144 "Mercury Marine" 143 "W. Gmeiner GmbH & Co." 142 "TRW Automotive (Commercial Steering Systems)" 141 "Thales Navigation Ltd." 140 "Lowrance Electronics, Inc." 139 "Caterpillar Trimble Control Technologies (CTCT), LLC" 138 "Georg Fritzmeier GmbH & Co. KG" 137 "Maretron" 136 "Komatsu Ltd." 135 "Airmar Technology Corporation" 134 "Iris Technology Ltd." 133 "Bucher Schoerling GmbH" 132 "Mulag-Fahrzeugwerk" 131 "ITT Industries" 130 "Nido - Universal Machines B.V." 129 "OMNEX Control Systems, Inc." 128 "Gerhard Duecker GmbH & Co. KG" 127 "Holland USA" 126 "Driver Tech" 125 "Nevada Automotive Test Center" 124 "Hydac Electronic" 123 "Basler Electric" 122 "FG Wilson (Engineering) Limited" 121 "HED (Hydro Electronic Devices, Inc.)" 120 "RDS Technology Ltd." 119 "IntegriNautics" 118 "Intron GmbH" 117 "HUSCO International" 116 "BEELINE Technologies" 115 "NACCO Materials Handling Group, Inc." 114 "EControls, Inc." 113 "Stress-Tek, Inc." 112 "MECALAC" 111 "Maschinenfabrik Bernhard Krone GmbH" 110 "EPIQ Sensor-Nite" 109 "TeeJet Technologies Denmark" 108 "WTK-Elecktronik GmbH" 107 "Grimme Landmaschinen GmbH & Co. KG" 106 "BAE Systems Controls, Inc." 105 "Kiepe Elektrik GmbH & Co. KG" 104 "Claas Selbstfahrende Erntemaschinen GmbH" 103 "Agrocom GmbH & Co. Agrarsystem KG" 102 "AGCO GmbH & Co." 101 "Sensoria" 100 "VDO Technik AG" 99 "International Transmissions Ltd (ITL)" 98 "Mueller-Elektronik GmbH & Co." 97 "Ag Leader Technology, Inc." 96 "Mech@tronic IT GmbH" 95 "Pacific Insight Electronics Corp." 94 "CNH Global N.V." 93 "Perkins Engines Company Ltd." 92 "Ag-Chem Equipment Co., Inc." 91 "BSG Bodensee Steuergeraete GmbH" 90 "Knorr-Bremse SfN GmbH" 89 "Kverneland Group, Electronics Division" 88 "Satloc Precision GPS" 87 "J.C. Bamford Excavators Ltd (JCB)" 86 "C.E. Niehoff & Company" 85 "Kohler Co." 84 "New Holland UK Limited" 83 "Eaton VORAD Technologies" 82 "Bobcat/Ingersoll-Rand" 81 "Fire Research Corp" 80 "Twin Disc, Inc." 79 "Daimler Benz AG - Engine Division (PBM)" 78 "Frank W. Murphy Manufacturing, Inc." 77 "Deere Power Systems Group" 76 "unused" 75 "Deere & Co. Agricultural Division" 74 "Eaton Axle-Brake Division" 73 "LeTourneau, Inc." 72 "Sisu Corporation" 71 "Vansco Electronics Ltd." 70 "Flex-Coil Limited" 69 "Trimble Navigation" 68 "Scania" 67 "Funk Manufacturing Company" 66 "John Deere Construction Equipment Division" 65 "MAN Nutzfahrzeuge AG" 64 "unused" 63 "ZF Industries Inc." 62 "Wabco" 61 "Volvo Truck Corp." 60 "Volvo Trucks North America Inc." 59 "VES Inc." 58 "SPX Corporation, OTC Division" 57 "Sauer-Danfoss Co." 56 "SAIC" 55 "Ryder System Inc." 54 "Meritor Wabco" 53 "Continental Automotive Systems US, Inc." 52 "Meritor Automotive, Inc." 51 "Robert Bosch GmbH" 50 "Robert Bosch Corp" 49 "RE America Inc." 48 "Pollak Alphabet" 47 "Phillips Semiconductor" 46 "Parasoft Computing Solutions" 45 "PACCAR" 44 "Nippondenso Co. Ltd." 43 "International Truck and Engine Corp. Vehicle Electronics" 42 "International Truck and Engine Corp. Engine Electronics" 41 "Motorola Inc." 40 "Motorola AIEG Inc." 39 "Microfirm Inc." 38 "Micro Processor Systems Inc." 37 "Mack Trucks Inc." 36 "Lucas Ltd." 35 "Kenworth Truck Co." 34 "Kelsey Hayes Co." 33 "John Deere" 32 "Jacobs Vehicle Systems" 31 "J Pollak Corp." 30 "Isuzu Motors Ltd." 29 "Hino Motors Ltd." 28 "Grote Ind. Inc." 27 "GMC" 26 "General Motors Corp., Service Technology Group" 25 "Daimler Trucks North America LLC" 24 "Ford Motor Co., Vehicle Controls" 23 "Ford Motor Co., Heavy Truck" 22 "Ford Motor Co., Electronic Concepts $ Systems" 21 "Echilin Inc., Midland Brake Inc." 20 "Eaton Ltd" 19 "Eaton Corp. Trucking Info Services" 18 "Eaton Corp, Transmission Division" 17 "Eaton Corp. Res & Dev" 16 "Eaton Corp." 15 "Dickey-John Corp." 14 "Detroit Diesel Corporation" 13 "Delco Electronics" 12 "Deere & Company, Precision Farming" 11 "Dearborn Group Inc." 10 "Cummins Engine Co." 9 "Chrysler Corp." 8 "Caterpillar Inc." 7 "Case Corp." 6 "Berifors Electronics AB" 5 "AMP Inc." 4 "Ametek-Dixson" 3 "Ametek, US Gauge Division" 2 "Allison Transmission, GMC" 1 "Allied Signal Inc." 0 "Reserved" 231 "Topcon Positioning Systems, Inc." 230 "Saucon Technologies" 229 "Garmin International Inc." 228 "ZF Marine Electronics" 227 "Lykketronic A/S" 226 "Monaco Coach Corporation" 225 "SKF" 224 "EMMI Network, S.L." 223 "Vaueo Retarder Co., Ltd." 263 "IMMI" 262 "HydraForce, Inc" 261 "Red Dot Corporation" 260 "Reichhardt GmbH" 259 "Jetter AG" 258 "ARAG" 257 "Honda Motor Co., Ltd" 256 "Tyco Electronics AMP" 255 "MEAS France" 254 "GE Sensing" 253 "Mobile Control Systems" 298 "Holley Performance" 297 "Zonar Systems Inc" 296 "micro dynamics GmbH" 295 "BEP Marine" 294 "Grayhill Inc." 293 "Spyder Controls Corp." 292 "IKUSI - Angel Iglesias S.A." 291 "Groeneveld Transport Efficiency BV" 290 "Kuebler GmbH" 289 "Watlow" 288 "Mitsubishi FUSO Truck & Bus Corp." 287 "NTech Industries, Inc" 286 "Coelmo srl" 285 "Sea Recovery Corp" 284 "Mobile Tech Chile" 283 "CWF Hamilton & Co Ltd" 282 "Medallion Instrumentation Systems" 281 "Precision Governors LLC" 311 "Patrick Power Products" 310 "TECNORD srl" 309 "Krauss-Maffei Wegmann GmbH & Co. KG" 308 "Cyntrx" 307 "MAS Technologies" 306 "Sleipner Motor AB" 305 "NovAtel Inc" 304 "EmpirBus AB" 303 "CTS Corporation" 302 "Nissin Kogyo Co., LTD" 301 "Parker Hannifin (UK) Ltd FDE group" 300 "Systron Donner Automotive" 299 "Rauch Landmaschinen GmbH" 280 "Leica Geosystems Pty Ltd" 279 "Geometris LP" 278 "Takata Electronics" 277 "LHP Telematics" 276 "Aqua-Hot Heating Systems" 275 "Navico Egersund AS" 274 "LTW Technology Co., LTD" 273 "Active Research Limited" 272 "Gross Mechanical Laboratories, Inc" 327 "Sonceboz SA" 326 "Akron Brass Company" 325 "ASM Automation Sensorik Messtechnik GmbH" 324 "Snap-on Diagnostics" 323 "Mobileye Vision Technologies Ltd." 322 "MICHENKA s.r.o." 321 "Ultra Electronics, Electrics" 320 "Miedema Landbouwwerktuigenfabriek B.V." 319 "Cadec Global" 318 "SAT Plan" 317 "Navtronics Bvba" 316 "ITT Flow Control" 315 "Icom Incorporated" 314 "CSM GmbH" 313 "Ilmor Engineering, Inc" 312 "Lectronix, Inc." 271 "Cole Hersee" 270 "Tennant" 269 "Saft America Inc.,  Space & Defense Division" 268 "Accurate Technologies" 267 "Red Lion Controls, Inc" 266 "International Thermal Research Ltd" 265 "MTS Sensor Technologie GmbH" 264 "Autolync" 248 "Cooper Standard Automotive Active Systems Group" 247 "ePULSE" 246 "Class 1, Inc" 245 "Capstan Ag Systems, Inc." 244 "Techno-Matic" 243 "eRide, Inc." 242 "Kokusandenki Co. Ltd" 241 "Schneider Automation SAS " 240 "Vanair Mfg" 239 "May & Scofield Ltd" 238 "ZF Friedrichshafen AG" 237 "Agtron Enterprises Inc" 236 "Norac Systems International Inc" 235 "SailorMade Marine Telemetry - Tetra Technology Ltd." 234 "Mondial electronic GmbH" ;
VAL_ 2565799678 Function 127 "Reserved" 126 "Reserved" 125 "Reserved" 124 "Reserved" 123 "Reserved" 122 "Reserved" 121 "Reserved" 120 "Reserved" 119 "Reserved" 118 "Reserved" 117 "Reserved" 116 "Reserved" 115 "Reserved" 114 "Reserved" 113 "Reserved" 112 "Reserved" 111 "Reserved" 110 "Reserved" 109 "Reserved" 108 "Reserved" 107 "Reserved" 106 "Reserved" 105 "Reserved" 104 "Reserved" 103 "Reserved" 102 "Reserved" 101 "Reserved" 42 "Water Pump Control" 41 "Lighting - Operator Controls" 40 "Seat Control" 39 "Ignition Control Module" 38 "Tire Pressure Control" 37 "Cab Controller" 36 "Pneumatic - System Controller" 35 "Suspension - System Controller" 34 "Hydraulic Pump Controller" 33 "System Monitor" 32 "Headway Controller" 31 "Propulsion Battery Charger" 30 "Management Computer" 29 "Virtual Terminal (in cab)" 28 "Off Vehicle Gateway" 27 "Power TakeOff (Secondary or Front)" 26 "Body Controller" 25 "Network Interconnect ECU" 24 "Vehicle Security" 23 "Vehicle Navigation" 22 "Aerodynamic Control" 21 "Cab Climate Control" 20 "Trip Recorder" 19 "Instrument Cluster" 18 "Suspension - Drive Axle" 17 "Suspension - Steer Axle" 16 "Steering Controller" 15 "Fuel System" 14 "Cruise Control" 13 "Retarder - Driveline" 12 "Retarder - Engine" 11 "Brakes - Drive Axle" 10 "Brakes - Steer Axle" 9 "Brakes - System Controller" 8 "Axle - Drive" 7 "Axle - Steering" 6 "Power TakeOff - (Main or Rear)" 5 "Shift Control/Console" 4 "Battery Pack Monitor" 3 "Transmission" 2 "Electric Propulsion Control" 1 "Auxiliary Power Unit (APU)" 0 "Engine" 100 "Reserved" 99 "Reserved" 98 "Reserved" 97 "Reserved" 96 "Reserved" 95 "Reserved" 94 "Reserved" 93 "Reserved" 92 "Reserved" 91 "Reserved" 90 "Reserved" 89 "Reserved" 88 "Reserved" 87 "Reserved" 86 "Reserved" 85 "Reserved" 84 "Reserved" 83 "Reserved" 82 "Reserved" 81 "Reserved" 80 "Reserved" 79 "Reserved" 78 "Reserved" 77 "Reserved" 76 "Reserved" 75 "Supplemental Fan" 74 "Lubrication System" 73 "Rollover Detection Control" 72 "Coolant Valve Controller" 71 "Transfer Case Control" 70 "Auxiliary Regeneration Device" 69 "Engine Emission Aftertreatement System" 68 "Aftertreatment system gas measurement" 67 "Electrical System Controller" 66 "I/O Controller" 65 "Gas Flow Measurement" 64 "Endurance Braking" 63 "Engine Valve Controller" 62 "On-Board Diagnostic Unit" 61 "File Server/Printer" 60 "Cab Display" 59 "Starter" 58 "Fan Drive Control" 57 "Steering Column Unit" 56 "Communications Unit, Radio" 55 "Communications Unit, Satellite" 54 "Communications Unit, Cellular" 53 "Alternator/Charging System" 52 "Chassis Controller" 51 "Forward-Looking Collision Warning System" 50 "Auxiliary Heater" 49 "Clutch/Converter Control" 48 "Ramp Control" 47 "Information System Controller" 46 "Oil Sensor Unit" 45 "Vehicle Dynamic Stability Control" 44 "Exhaust Emission Control" 43 "Transmission Display" ;
VAL_ 2565799678 IndustryGroup 6 "Reserved for SAE" 7 "Reserved for SAE" 5 "IndustrialProcessCtrlStationary" 4 "Marine" 3 "Construction" 2 "Agricultural and Forestry" 1 "On-Highway" 0 "Global" ;
VAL_ 2565799673 IndustryGroup 6 "Reserved for SAE" 7 "Reserved for SAE" 5 "IndustrialProcessCtrlStationary" 4 "Marine" 3 "Construction" 2 "Agricultural and Forestry" 1 "On-Highway" 0 "Global" ;
VAL_ 2565799673 Function 127 "Reserved" 126 "Reserved" 125 "Reserved" 124 "Reserved" 123 "Reserved" 122 "Reserved" 121 "Reserved" 120 "Reserved" 119 "Reserved" 118 "Reserved" 117 "Reserved" 116 "Reserved" 115 "Reserved" 114 "Reserved" 113 "Reserved" 112 "Reserved" 111 "Reserved" 110 "Reserved" 109 "Reserved" 108 "Reserved" 107 "Reserved" 106 "Reserved" 105 "Reserved" 104 "Reserved" 103 "Reserved" 102 "Reserved" 101 "Reserved" 42 "Water Pump Control" 41 "Lighting - Operator Controls" 40 "Seat Control" 39 "Ignition Control Module" 38 "Tire Pressure Control" 37 "Cab Controller" 36 "Pneumatic - System Controller" 35 "Suspension - System Controller" 34 "Hydraulic Pump Controller" 33 "System Monitor" 32 "Headway Controller" 31 "Propulsion Battery Charger" 30 "Management Computer" 29 "Virtual Terminal (in cab)" 28 "Off Vehicle Gateway" 27 "Power TakeOff (Secondary or Front)" 26 "Body Controller" 25 "Network Interconnect ECU" 24 "Vehicle Security" 23 "Vehicle Navigation" 22 "Aerodynamic Control" 21 "Cab Climate Control" 20 "Trip Recorder" 19 "Instrument Cluster" 18 "Suspension - Drive Axle" 17 "Suspension - Steer Axle" 16 "Steering Controller" 15 "Fuel System" 14 "Cruise Control" 13 "Retarder - Driveline" 12 "Retarder - Engine" 11 "Brakes - Drive Axle" 10 "Brakes - Steer Axle" 9 "Brakes - System Controller" 8 "Axle - Drive" 7 "Axle - Steering" 6 "Power TakeOff - (Main or Rear)" 5 "Shift Control/Console" 4 "Battery Pack Monitor" 3 "Transmission" 2 "Electric Propulsion Control" 1 "Auxiliary Power Unit (APU)" 0 "Engine" 100 "Reserved" 99 "Reserved" 98 "Reserved" 97 "Reserved" 96 "Reserved" 95 "Reserved" 94 "Reserved" 93 "Reserved" 92 "Reserved" 91 "Reserved" 90 "Reserved" 89 "Reserved" 88 "Reserved" 87 "Reserved" 86 "Reserved" 85 "Reserved" 84 "Reserved" 83 "Reserved" 82 "Reserved" 81 "Reserved" 80 "Reserved" 79 "Reserved" 78 "Reserved" 77 "Reserved" 76 "Reserved" 75 "Supplemental Fan" 74 "Lubrication System" 73 "Rollover Detection Control" 72 "Coolant Valve Controller" 71 "Transfer Case Control" 70 "Auxiliary Regeneration Device" 69 "Engine Emission Aftertreatement System" 68 "Aftertreatment system gas measurement" 67 "Electrical System Controller" 66 "I/O Controller" 65 "Gas Flow Measurement" 64 "Endurance Braking" 63 "Engine Valve Controller" 62 "On-Board Diagnostic Unit" 61 "File Server/Printer" 60 "Cab Display" 59 "Starter" 58 "Fan Drive Control" 57 "Steering Column Unit" 56 "Communications Unit, Radio" 55 "Communications Unit, Satellite" 54 "Communications Unit, Cellular" 53 "Alternator/Charging System" 52 "Chassis Controller" 51 "Forward-Looking Collision Warning System" 50 "Auxiliary Heater" 49 "Clutch/Converter Control" 48 "Ramp Control" 47 "Information System Controller" 46 "Oil Sensor Unit" 45 "Vehicle Dynamic Stability Control" 44 "Exhaust Emission Control" 43 "Transmission Display" ;
VAL_ 2565799673 ManufacturerCode 381 "B&G" 374 "Northern Lights" 373 "Electronic Design" 371 "Delphi" 370 "Heinzmann GmbH & Co. KG" 369 "Power Torque Engineering Ltd" 368 "HANSENHOF_electronic" 367 "Fliegl Agrartechnik" 366 "Viewnyx Corp." 365 "Digi-Star, LLC" 364 "OEM Controls Inc." 363 "BEI Duncan" 362 "Alois Poettinger Maschinenfabrik GmbH" 361 "InMach" 360 "HJS Fahrzeugtechnik GmbH & Co KG" 359 "Ludwig Bergmann GmbH" 358 "Victron Energy BV" 357 "Hardi International A/S" 356 "Fischer Panda Generators, Inc" 355 "Mastervolt International B.V." 354 "Junkkari OY" 353 "Hegemon Electronics, Inc." 352 "SAME DEUTZ-FAHR" 351 "Thrane & Thrane" 350 "Noris Marine Systems GmbH & Co KG" 349 "Suonentiet" 348 "Amazonen Werke H. Dreyer" 347 "Honeywell" 346 "Control Solutions" 345 "Korean Maritime University" 344 "Parvus Corporation" 343 "Baumer Group" 342 "THOMAS MAGNETE GmbH" 341 "Boning GmbH & Co" 340 "Continental AG" 339 "Competence Center ISOBUS e.V." 338 "GRAF-SYTECO" 337 "Carraro S.p.A." 336 "APE s.r.o." 335 "Evo Electric Ltd" 334 "Takata-Petri AG" 333 "Hadley Products Corporation" 332 "HWH Corporation" 331 "Horton, Inc." 330 "Kidde Aerospace and Defense" 329 "Deif A/S" 328 "Qwerty Electronik AB" 252 "Sensor-Technik Wiedemann GmbH" 251 "German Agricultural Society" 250 "Kuhn Group" 249 "Schaltbau GmbH" 233 "Yacht Monitoring Solutions Inc." 232 "TSD Integrated Controls" 1863 "Thomas G. Faria Co." 1862 "Sanshin" 1861 "Vector CANtech" 1860 "MMP" 1859 "Kvasar AB" 1858 "Litton" 1857 "Simrad" 1856 "Trimble" 1855 "Furuno USA" 1854 "Northstar Technologies" 1853 "Japan Radio Co." 1852 "Navionics" 1851 "Raymarine" 1850 "Teleflex" 222 "Generac Power Systems, Inc." 221 "SiE" 220 "Beede Electrical Instrument Company, Inc." 219 "Cat OEM Solutions" 218 "Gits Manufacturing Company" 217 "RM Michaelides Software & Elektronik GmbH" 216 "Paneltronics Inc." 215 "Aetna Engineering/Fireboy-Xintex" 214 "MC elettronica Srl" 213 "CNH Belgium N.V." 212 "Sure Power Industries, Inc." 211 "DNA Group" 210 "Iteris, Inc." 209 "Bell Equip. Co. SA (PTY) LTD" 208 "Drew Technologies, Inc." 207 "Otto Engineering" 206 "port GmbH" 205 "SmarTire Systems Inc" 204 "The Morey Corporation" 203 "MILtronik GmbH" 202 "Curtis Instruments, Inc." 201 "Disenos y Tecnologia S.A." 200 "MGM Brakes" 199 "Actia Corp." 198 "Mystic Valley Communications" 197 "Mechron Power Systems" 196 "LEMKEN GmbH & Co. KG" 195 "General Engine Products" 194 "TriMark Corporation" 193 "Nobletec" 192 "Floscan" 191 "XATA Corporation" 190 "Hella KGaA Hueck & Co." 189 "QUALCOMM" 188 "EMP Corp." 187 "Air-Weigh" 186 "Altronic, Inc." 185 "Beede Electrical Instrument Company" 184 "EIA Electronics" 183 "KDS Controls, Inc." 182 "Vehicle Systems Engineering B.V." 181 "Coretronics, Inc." 180 "Smart Power Systems" 179 "TeeJet Technologies Denmark" 178 "Siemens VDO Automotive AG" 177 "Diagnostic System Associates" 176 "Moritz Aerospace" 175 "Veris Technologies, Inc." 174 "AB Volvo Penta" 173 "Ryeso, Inc." 172 "Yanmar Marine USA" 171 "Wachendorff Elektronik GmbH & Co. KG" 170 "Computronics Corporation Ltd." 169 "Marlin Technologies Inc." 168 "Xantrex" 167 "JLG Industries Inc." 166 "Phoenix International" 165 "CPAC Systems AB" 164 "DaimlerChrysler Off-Highway" 163 "BRP Inc." 162 "Axiomatic Technologies" 161 "Offshore Systems (UK) Limited" 160 "Nido" 159 "NTech Industries Inc." 158 "Firestone Industrial Products Company" 157 "ISSPRO Inc." 156 "ITT Industries - Cannon" 155 "Vetronix Corporation" 154 "Westerbeke Corporation" 153 "Woodward, Industrial Controls Division" 152 "elobau GmbH & Co. KG" 151 "Raven Industries Inc. - Flow Controls Division" 150 "Fleetguard" 149 "Holset" 148 "Blue Water Data, Inc." 147 "Nautibus Electronic GmbH" 146 "Maxima Technologies" 145 "MurCal Controls" 144 "Mercury Marine" 143 "W. Gmeiner GmbH & Co." 142 "TRW Automotive (Commercial Steering Systems)" 141 "Thales Navigation Ltd." 140 "Lowrance Electronics, Inc." 139 "Caterpillar Trimble Control Technologies (CTCT), LLC" 138 "Georg Fritzmeier GmbH & Co. KG" 137 "Maretron" 136 "Komatsu Ltd." 135 "Airmar Technology Corporation" 134 "Iris Technology Ltd." 133 "Bucher Schoerling GmbH" 132 "Mulag-Fahrzeugwerk" 131 "ITT Industries" 130 "Nido - Universal Machines B.V." 129 "OMNEX Control Systems, Inc." 128 "Gerhard Duecker GmbH & Co. KG" 127 "Holland USA" 126 "Driver Tech" 125 "Nevada Automotive Test Center" 124 "Hydac Electronic" 123 "Basler Electric" 122 "FG Wilson (Engineering) Limited" 121 "HED (Hydro Electronic Devices, Inc.)" 120 "RDS Technology Ltd." 119 "IntegriNautics" 118 "Intron GmbH" 117 "HUSCO International" 116 "BEELINE Technologies" 115 "NACCO Materials Handling Group, Inc." 114 "EControls, Inc." 113 "Stress-Tek, Inc." 112 "MECALAC" 111 "Maschinenfabrik Bernhard Krone GmbH" 110 "EPIQ Sensor-Nite" 109 "TeeJet Technologies Denmark" 108 "WTK-Elecktronik GmbH" 107 "Grimme Landmaschinen GmbH & Co. KG" 106 "BAE Systems Controls, Inc." 105 "Kiepe Elektrik GmbH & Co. KG" 104 "Claas Selbstfahrende Erntemaschinen GmbH" 103 "Agrocom GmbH & Co. Agrarsystem KG" 102 "AGCO GmbH & Co." 101 "Sensoria" 100 "VDO Technik AG" 99 "International Transmissions Ltd (ITL)" 98 "Mueller-Elektronik GmbH & Co." 97 "Ag Leader Technology, Inc." 96 "Mech@tronic IT GmbH" 95 "Pacific Insight Electronics Corp." 94 "CNH Global N.V." 93 "Perkins Engines Company Ltd." 92 "Ag-Chem Equipment Co., Inc." 91 "BSG Bodensee Steuergeraete GmbH" 90 "Knorr-Bremse SfN GmbH" 89 "Kverneland Group, Electronics Division" 88 "Satloc Precision GPS" 87 "J.C. Bamford Excavators Ltd (JCB)" 86 "C.E. Niehoff & Company" 85 "Kohler Co." 84 "New Holland UK Limited" 83 "Eaton VORAD Technologies" 82 "Bobcat/Ingersoll-Rand" 81 "Fire Research Corp" 80 "Twin Disc, Inc." 79 "Daimler Benz AG - Engine Division (PBM)" 78 "Frank W. Murphy Manufacturing, Inc." 77 "Deere Power Systems Group" 76 "unused" 75 "Deere & Co. Agricultural Division" 74 "Eaton Axle-Brake Division" 73 "LeTourneau, Inc." 72 "Sisu Corporation" 71 "Vansco Electronics Ltd." 70 "Flex-Coil Limited" 69 "Trimble Navigation" 68 "Scania" 67 "Funk Manufacturing Company" 66 "John Deere Construction Equipment Division" 65 "MAN Nutzfahrzeuge AG" 64 "unused" 63 "ZF Industries Inc." 62 "Wabco" 61 "Volvo Truck Corp." 60 "Volvo Trucks North America Inc." 59 "VES Inc." 58 "SPX Corporation, OTC Division" 57 "Sauer-Danfoss Co." 56 "SAIC" 55 "Ryder System Inc." 54 "Meritor Wabco" 53 "Continental Automotive Systems US, Inc." 52 "Meritor Automotive, Inc." 51 "Robert Bosch GmbH" 50 "Robert Bosch Corp" 49 "RE America Inc." 48 "Pollak Alphabet" 47 "Phillips Semiconductor" 46 "Parasoft Computing Solutions" 45 "PACCAR" 44 "Nippondenso Co. Ltd." 43 "International Truck and Engine Corp. Vehicle Electronics" 42 "International Truck and Engine Corp. Engine Electronics" 41 "Motorola Inc." 40 "Motorola AIEG Inc." 39 "Microfirm Inc." 38 "Micro Processor Systems Inc." 37 "Mack Trucks Inc." 36 "Lucas Ltd." 35 "Kenworth Truck Co." 34 "Kelsey Hayes Co." 33 "John Deere" 32 "Jacobs Vehicle Systems" 31 "J Pollak Corp." 30 "Isuzu Motors Ltd." 29 "Hino Motors Ltd." 28 "Grote Ind. Inc." 27 "GMC" 26 "General Motors Corp., Service Technology Group" 25 "Daimler Trucks North America LLC" 24 "Ford Motor Co., Vehicle Controls" 23 "Ford Motor Co., Heavy Truck" 22 "Ford Motor Co., Electronic Concepts $ Systems" 21 "Echilin Inc., Midland Brake Inc." 20 "Eaton Ltd" 19 "Eaton Corp. Trucking Info Services" 18 "Eaton Corp, Transmission Division" 17 "Eaton Corp. Res & Dev" 16 "Eaton Corp." 15 "Dickey-John Corp." 14 "Detroit Diesel Corporation" 13 "Delco Electronics" 12 "Deere & Company, Precision Farming" 11 "Dearborn Group Inc." 10 "Cummins Engine Co." 9 "Chrysler Corp." 8 "Caterpillar Inc." 7 "Case Corp." 6 "Berifors Electronics AB" 5 "AMP Inc." 4 "Ametek-Dixson" 3 "Ametek, US Gauge Division" 2 "Allison Transmission, GMC" 1 "Allied Signal Inc." 0 "Reserved" 231 "Topcon Positioning Systems, Inc." 230 "Saucon Technologies" 229 "Garmin International Inc." 228 "ZF Marine Electronics" 227 "Lykketronic A/S" 226 "Monaco Coach Corporation" 225 "SKF" 224 "EMMI Network, S.L." 223 "Vaueo Retarder Co., Ltd." 263 "IMMI" 262 "HydraForce, Inc" 261 "Red Dot Corporation" 260 "Reichhardt GmbH" 259 "Jetter AG" 258 "ARAG" 257 "Honda Motor Co., Ltd" 256 "Tyco Electronics AMP" 255 "MEAS France" 254 "GE Sensing" 253 "Mobile Control Systems" 298 "Holley Performance" 297 "Zonar Systems Inc" 296 "micro dynamics GmbH" 295 "BEP Marine" 294 "Grayhill Inc." 293 "Spyder Controls Corp." 292 "IKUSI - Angel Iglesias S.A." 291 "Groeneveld Transport Efficiency BV" 290 "Kuebler GmbH" 289 "Watlow" 288 "Mitsubishi FUSO Truck & Bus Corp." 287 "NTech Industries, Inc" 286 "Coelmo srl" 285 "Sea Recovery Corp" 284 "Mobile Tech Chile" 283 "CWF Hamilton & Co Ltd" 282 "Medallion Instrumentation Systems" 281 "Precision Governors LLC" 311 "Patrick Power Products" 310 "TECNORD srl" 309 "Krauss-Maffei Wegmann GmbH & Co. KG" 308 "Cyntrx" 307 "MAS Technologies" 306 "Sleipner Motor AB" 305 "NovAtel Inc" 304 "EmpirBus AB" 303 "CTS Corporation" 302 "Nissin Kogyo Co., LTD" 301 "Parker Hannifin (UK) Ltd FDE group" 300 "Systron Donner Automotive" 299 "Rauch Landmaschinen GmbH" 280 "Leica Geosystems Pty Ltd" 279 "Geometris LP" 278 "Takata Electronics" 277 "LHP Telematics" 276 "Aqua-Hot Heating Systems" 275 "Navico Egersund AS" 274 "LTW Technology Co., LTD" 273 "Active Research Limited" 272 "Gross Mechanical Laboratories, Inc" 327 "Sonceboz SA" 326 "Akron Brass Company" 325 "ASM Automation Sensorik Messtechnik GmbH" 324 "Snap-on Diagnostics" 323 "Mobileye Vision Technologies Ltd." 322 "MICHENKA s.r.o." 321 "Ultra Electronics, Electrics" 320 "Miedema Landbouwwerktuigenfabriek B.V." 319 "Cadec Global" 318 "SAT Plan" 317 "Navtronics Bvba" 316 "ITT Flow Control" 315 "Icom Incorporated" 314 "CSM GmbH" 313 "Ilmor Engineering, Inc" 312 "Lectronix, Inc." 271 "Cole Hersee" 270 "Tennant" 269 "Saft America Inc.,  Space & Defense Division" 268 "Accurate Technologies" 267 "Red Lion Controls, Inc" 266 "International Thermal Research Ltd" 265 "MTS Sensor Technologie GmbH" 264 "Autolync" 248 "Cooper Standard Automotive Active Systems Group" 247 "ePULSE" 246 "Class 1, Inc" 245 "Capstan Ag Systems, Inc." 244 "Techno-Matic" 243 "eRide, Inc." 242 "Kokusandenki Co. Ltd" 241 "Schneider Automation SAS " 240 "Vanair Mfg" 239 "May & Scofield Ltd" 238 "ZF Friedrichshafen AG" 237 "Agtron Enterprises Inc" 236 "Norac Systems International Inc" 235 "SailorMade Marine Telemetry - Tetra Technology Ltd." 234 "Mondial electronic GmbH" ;
VAL_ 2565799673 VehicleSystem 0 "Non-specific System" 127 "Not Available" ;
VAL_ 2565799673 VehicleSystem5 127 "Not Available" 0 "Ind. Process Control Stationary" ;
VAL_ 2565799673 VehicleSystem4 100 "Deck/Cargo/Fishing equip. sys" 90 "Environmental (HVAC) Systems" 80 "Instrumentation/General Systems" 70 "Communications Systems" 60 "Navigation Systems" 50 "Propulsion Systems" 40 "Steering Systems" 30 "Power Mgmt and lighting systems" 25 "Gateway" 20 "Safety Systems" 10 "System Tools" 127 "Not Available" 0 "Non-specific System" ;
VAL_ 2565799673 VehicleSystem3 8 "Grader" 7 "Four Wheel Drive Loader" 6 "Forklift" 5 "Excavator" 4 "Crawler" 3 "Backhoe" 2 "Articulated Dump Truck" 1 "Skid Steer Loader" 127 "Not Available" 0 "Non-specific System" ;
VAL_ 2565799673 VehicleSystem2 16 "Skidder" 15 "Earth Work" 14 "Special Crops" 13 "Powered Auxiliary Device" 12 "Farm Yard Operations" 11 "Transport/Trailer" 10 "Irrigation" 9 "Forage" 8 "Root Harvesters" 7 "Harvesters" 6 "Sprayers" 5 "Fertilizers" 4 "Planters/Seeders" 3 "Secondary Tillage" 2 "Tillage" 1 "Tractor" 127 "Not Available" 0 "Non-specific System" ;
VAL_ 2565799673 VehicleSystem1 2 "Trailer" 1 "Tractor" 127 "Not Available" 0 "Non-specific System" ;
VAL_ 2565799552 IndustryGroup 6 "Reserved for SAE" 7 "Reserved for SAE" 5 "IndustrialProcessCtrlStationary" 4 "Marine" 3 "Construction" 2 "Agricultural and Forestry" 1 "On-Highway" 0 "Global" ;
VAL_ 2565799552 Function 127 "Reserved" 126 "Reserved" 125 "Reserved" 124 "Reserved" 123 "Reserved" 122 "Reserved" 121 "Reserved" 120 "Reserved" 119 "Reserved" 118 "Reserved" 117 "Reserved" 116 "Reserved" 115 "Reserved" 114 "Reserved" 113 "Reserved" 112 "Reserved" 111 "Reserved" 110 "Reserved" 109 "Reserved" 108 "Reserved" 107 "Reserved" 106 "Reserved" 105 "Reserved" 104 "Reserved" 103 "Reserved" 102 "Reserved" 101 "Reserved" 42 "Water Pump Control" 41 "Lighting - Operator Controls" 40 "Seat Control" 39 "Ignition Control Module" 38 "Tire Pressure Control" 37 "Cab Controller" 36 "Pneumatic - System Controller" 35 "Suspension - System Controller" 34 "Hydraulic Pump Controller" 33 "System Monitor" 32 "Headway Controller" 31 "Propulsion Battery Charger" 30 "Management Computer" 29 "Virtual Terminal (in cab)" 28 "Off Vehicle Gateway" 27 "Power TakeOff (Secondary or Front)" 26 "Body Controller" 25 "Network Interconnect ECU" 24 "Vehicle Security" 23 "Vehicle Navigation" 22 "Aerodynamic Control" 21 "Cab Climate Control" 20 "Trip Recorder" 19 "Instrument Cluster" 18 "Suspension - Drive Axle" 17 "Suspension - Steer Axle" 16 "Steering Controller" 15 "Fuel System" 14 "Cruise Control" 13 "Retarder - Driveline" 12 "Retarder - Engine" 11 "Brakes - Drive Axle" 10 "Brakes - Steer Axle" 9 "Brakes - System Controller" 8 "Axle - Drive" 7 "Axle - Steering" 6 "Power TakeOff - (Main or Rear)" 5 "Shift Control/Console" 4 "Battery Pack Monitor" 3 "Transmission" 2 "Electric Propulsion Control" 1 "Auxiliary Power Unit (APU)" 0 "Engine" 100 "Reserved" 99 "Reserved" 98 "Reserved" 97 "Reserved" 96 "Reserved" 95 "Reserved" 94 "Reserved" 93 "Reserved" 92 "Reserved" 91 "Reserved" 90 "Reserved" 89 "Reserved" 88 "Reserved" 87 "Reserved" 86 "Reserved" 85 "Reserved" 84 "Reserved" 83 "Reserved" 82 "Reserved" 81 "Reserved" 80 "Reserved" 79 "Reserved" 78 "Reserved" 77 "Reserved" 76 "Reserved" 75 "Supplemental Fan" 74 "Lubrication System" 73 "Rollover Detection Control" 72 "Coolant Valve Controller" 71 "Transfer Case Control" 70 "Auxiliary Regeneration Device" 69 "Engine Emission Aftertreatement System" 68 "Aftertreatment system gas measurement" 67 "Electrical System Controller" 66 "I/O Controller" 65 "Gas Flow Measurement" 64 "Endurance Braking" 63 "Engine Valve Controller" 62 "On-Board Diagnostic Unit" 61 "File Server/Printer" 60 "Cab Display" 59 "Starter" 58 "Fan Drive Control" 57 "Steering Column Unit" 56 "Communications Unit, Radio" 55 "Communications Unit, Satellite" 54 "Communications Unit, Cellular" 53 "Alternator/Charging System" 52 "Chassis Controller" 51 "Forward-Looking Collision Warning System" 50 "Auxiliary Heater" 49 "Clutch/Converter Control" 48 "Ramp Control" 47 "Information System Controller" 46 "Oil Sensor Unit" 45 "Vehicle Dynamic Stability Control" 44 "Exhaust Emission Control" 43 "Transmission Display" ;
VAL_ 2565799552 ManufacturerCode 381 "B&G" 374 "Northern Lights" 373 "Electronic Design" 371 "Delphi" 370 "Heinzmann GmbH & Co. KG" 369 "Power Torque Engineering Ltd" 368 "HANSENHOF_electronic" 367 "Fliegl Agrartechnik" 366 "Viewnyx Corp." 365 "Digi-Star, LLC" 364 "OEM Controls Inc." 363 "BEI Duncan" 362 "Alois Poettinger Maschinenfabrik GmbH" 361 "InMach" 360 "HJS Fahrzeugtechnik GmbH & Co KG" 359 "Ludwig Bergmann GmbH" 358 "Victron Energy BV" 357 "Hardi International A/S" 356 "Fischer Panda Generators, Inc" 355 "Mastervolt International B.V." 354 "Junkkari OY" 353 "Hegemon Electronics, Inc." 352 "SAME DEUTZ-FAHR" 351 "Thrane & Thrane" 350 "Noris Marine Systems GmbH & Co KG" 349 "Suonentiet" 348 "Amazonen Werke H. Dreyer" 347 "Honeywell" 346 "Control Solutions" 345 "Korean Maritime University" 344 "Parvus Corporation" 343 "Baumer Group" 342 "THOMAS MAGNETE GmbH" 341 "Boning GmbH & Co" 340 "Continental AG" 339 "Competence Center ISOBUS e.V." 338 "GRAF-SYTECO" 337 "Carraro S.p.A." 336 "APE s.r.o." 335 "Evo Electric Ltd" 334 "Takata-Petri AG" 333 "Hadley Products Corporation" 332 "HWH Corporation" 331 "Horton, Inc." 330 "Kidde Aerospace and Defense" 329 "Deif A/S" 328 "Qwerty Electronik AB" 252 "Sensor-Technik Wiedemann GmbH" 251 "German Agricultural Society" 250 "Kuhn Group" 249 "Schaltbau GmbH" 233 "Yacht Monitoring Solutions Inc." 232 "TSD Integrated Controls" 1863 "Thomas G. Faria Co." 1862 "Sanshin" 1861 "Vector CANtech" 1860 "MMP" 1859 "Kvasar AB" 1858 "Litton" 1857 "Simrad" 1856 "Trimble" 1855 "Furuno USA" 1854 "Northstar Technologies" 1853 "Japan Radio Co." 1852 "Navionics" 1851 "Raymarine" 1850 "Teleflex" 222 "Generac Power Systems, Inc." 221 "SiE" 220 "Beede Electrical Instrument Company, Inc." 219 "Cat OEM Solutions" 218 "Gits Manufacturing Company" 217 "RM Michaelides Software & Elektronik GmbH" 216 "Paneltronics Inc." 215 "Aetna Engineering/Fireboy-Xintex" 214 "MC elettronica Srl" 213 "CNH Belgium N.V." 212 "Sure Power Industries, Inc." 211 "DNA Group" 210 "Iteris, Inc." 209 "Bell Equip. Co. SA (PTY) LTD" 208 "Drew Technologies, Inc." 207 "Otto Engineering" 206 "port GmbH" 205 "SmarTire Systems Inc" 204 "The Morey Corporation" 203 "MILtronik GmbH" 202 "Curtis Instruments, Inc." 201 "Disenos y Tecnologia S.A." 200 "MGM Brakes" 199 "Actia Corp." 198 "Mystic Valley Communications" 197 "Mechron Power Systems" 196 "LEMKEN GmbH & Co. KG" 195 "General Engine Products" 194 "TriMark Corporation" 193 "Nobletec" 192 "Floscan" 191 "XATA Corporation" 190 "Hella KGaA Hueck & Co." 189 "QUALCOMM" 188 "EMP Corp." 187 "Air-Weigh" 186 "Altronic, Inc." 185 "Beede Electrical Instrument Company" 184 "EIA Electronics" 183 "KDS Controls, Inc." 182 "Vehicle Systems Engineering B.V." 181 "Coretronics, Inc." 180 "Smart Power Systems" 179 "TeeJet Technologies Denmark" 178 "Siemens VDO Automotive AG" 177 "Diagnostic System Associates" 176 "Moritz Aerospace" 175 "Veris Technologies, Inc." 174 "AB Volvo Penta" 173 "Ryeso, Inc." 172 "Yanmar Marine USA" 171 "Wachendorff Elektronik GmbH & Co. KG" 170 "Computronics Corporation Ltd." 169 "Marlin Technologies Inc." 168 "Xantrex" 167 "JLG Industries Inc." 166 "Phoenix International" 165 "CPAC Systems AB" 164 "DaimlerChrysler Off-Highway" 163 "BRP Inc." 162 "Axiomatic Technologies" 161 "Offshore Systems (UK) Limited" 160 "Nido" 159 "NTech Industries Inc." 158 "Firestone Industrial Products Company" 157 "ISSPRO Inc." 156 "ITT Industries - Cannon" 155 "Vetronix Corporation" 154 "Westerbeke Corporation" 153 "Woodward, Industrial Controls Division" 152 "elobau GmbH & Co. KG" 151 "Raven Industries Inc. - Flow Controls Division" 150 "Fleetguard" 149 "Holset" 148 "Blue Water Data, Inc." 147 "Nautibus Electronic GmbH" 146 "Maxima Technologies" 145 "MurCal Controls" 144 "Mercury Marine" 143 "W. Gmeiner GmbH & Co." 142 "TRW Automotive (Commercial Steering Systems)" 141 "Thales Navigation Ltd." 140 "Lowrance Electronics, Inc." 139 "Caterpillar Trimble Control Technologies (CTCT), LLC" 138 "Georg Fritzmeier GmbH & Co. KG" 137 "Maretron" 136 "Komatsu Ltd." 135 "Airmar Technology Corporation" 134 "Iris Technology Ltd." 133 "Bucher Schoerling GmbH" 132 "Mulag-Fahrzeugwerk" 131 "ITT Industries" 130 "Nido - Universal Machines B.V." 129 "OMNEX Control Systems, Inc." 128 "Gerhard Duecker GmbH & Co. KG" 127 "Holland USA" 126 "Driver Tech" 125 "Nevada Automotive Test Center" 124 "Hydac Electronic" 123 "Basler Electric" 122 "FG Wilson (Engineering) Limited" 121 "HED (Hydro Electronic Devices, Inc.)" 120 "RDS Technology Ltd." 119 "IntegriNautics" 118 "Intron GmbH" 117 "HUSCO International" 116 "BEELINE Technologies" 115 "NACCO Materials Handling Group, Inc." 114 "EControls, Inc." 113 "Stress-Tek, Inc." 112 "MECALAC" 111 "Maschinenfabrik Bernhard Krone GmbH" 110 "EPIQ Sensor-Nite" 109 "TeeJet Technologies Denmark" 108 "WTK-Elecktronik GmbH" 107 "Grimme Landmaschinen GmbH & Co. KG" 106 "BAE Systems Controls, Inc." 105 "Kiepe Elektrik GmbH & Co. KG" 104 "Claas Selbstfahrende Erntemaschinen GmbH" 103 "Agrocom GmbH & Co. Agrarsystem KG" 102 "AGCO GmbH & Co." 101 "Sensoria" 100 "VDO Technik AG" 99 "International Transmissions Ltd (ITL)" 98 "Mueller-Elektronik GmbH & Co." 97 "Ag Leader Technology, Inc." 96 "Mech@tronic IT GmbH" 95 "Pacific Insight Electronics Corp." 94 "CNH Global N.V." 93 "Perkins Engines Company Ltd." 92 "Ag-Chem Equipment Co., Inc." 91 "BSG Bodensee Steuergeraete GmbH" 90 "Knorr-Bremse SfN GmbH" 89 "Kverneland Group, Electronics Division" 88 "Satloc Precision GPS" 87 "J.C. Bamford Excavators Ltd (JCB)" 86 "C.E. Niehoff & Company" 85 "Kohler Co." 84 "New Holland UK Limited" 83 "Eaton VORAD Technologies" 82 "Bobcat/Ingersoll-Rand" 81 "Fire Research Corp" 80 "Twin Disc, Inc." 79 "Daimler Benz AG - Engine Division (PBM)" 78 "Frank W. Murphy Manufacturing, Inc." 77 "Deere Power Systems Group" 76 "unused" 75 "Deere & Co. Agricultural Division" 74 "Eaton Axle-Brake Division" 73 "LeTourneau, Inc." 72 "Sisu Corporation" 71 "Vansco Electronics Ltd." 70 "Flex-Coil Limited" 69 "Trimble Navigation" 68 "Scania" 67 "Funk Manufacturing Company" 66 "John Deere Construction Equipment Division" 65 "MAN Nutzfahrzeuge AG" 64 "unused" 63 "ZF Industries Inc." 62 "Wabco" 61 "Volvo Truck Corp." 60 "Volvo Trucks North America Inc." 59 "VES Inc." 58 "SPX Corporation, OTC Division" 57 "Sauer-Danfoss Co." 56 "SAIC" 55 "Ryder System Inc." 54 "Meritor Wabco" 53 "Continental Automotive Systems US, Inc." 52 "Meritor Automotive, Inc." 51 "Robert Bosch GmbH" 50 "Robert Bosch Corp" 49 "RE America Inc." 48 "Pollak Alphabet" 47 "Phillips Semiconductor" 46 "Parasoft Computing Solutions" 45 "PACCAR" 44 "Nippondenso Co. Ltd." 43 "International Truck and Engine Corp. Vehicle Electronics" 42 "International Truck and Engine Corp. Engine Electronics" 41 "Motorola Inc." 40 "Motorola AIEG Inc." 39 "Microfirm Inc." 38 "Micro Processor Systems Inc." 37 "Mack Trucks Inc." 36 "Lucas Ltd." 35 "Kenworth Truck Co." 34 "Kelsey Hayes Co." 33 "John Deere" 32 "Jacobs Vehicle Systems" 31 "J Pollak Corp." 30 "Isuzu Motors Ltd." 29 "Hino Motors Ltd." 28 "Grote Ind. Inc." 27 "GMC" 26 "General Motors Corp., Service Technology Group" 25 "Daimler Trucks North America LLC" 24 "Ford Motor Co., Vehicle Controls" 23 "Ford Motor Co., Heavy Truck" 22 "Ford Motor Co., Electronic Concepts $ Systems" 21 "Echilin Inc., Midland Brake Inc." 20 "Eaton Ltd" 19 "Eaton Corp. Trucking Info Services" 18 "Eaton Corp, Transmission Division" 17 "Eaton Corp. Res & Dev" 16 "Eaton Corp." 15 "Dickey-John Corp." 14 "Detroit Diesel Corporation" 13 "Delco Electronics" 12 "Deere & Company, Precision Farming" 11 "Dearborn Group Inc." 10 "Cummins Engine Co." 9 "Chrysler Corp." 8 "Caterpillar Inc." 7 "Case Corp." 6 "Berifors Electronics AB" 5 "AMP Inc." 4 "Ametek-Dixson" 3 "Ametek, US Gauge Division" 2 "Allison Transmission, GMC" 1 "Allied Signal Inc." 0 "Reserved" 231 "Topcon Positioning Systems, Inc." 230 "Saucon Technologies" 229 "Garmin International Inc." 228 "ZF Marine Electronics" 227 "Lykketronic A/S" 226 "Monaco Coach Corporation" 225 "SKF" 224 "EMMI Network, S.L." 223 "Vaueo Retarder Co., Ltd." 263 "IMMI" 262 "HydraForce, Inc" 261 "Red Dot Corporation" 260 "Reichhardt GmbH" 259 "Jetter AG" 258 "ARAG" 257 "Honda Motor Co., Ltd" 256 "Tyco Electronics AMP" 255 "MEAS France" 254 "GE Sensing" 253 "Mobile Control Systems" 298 "Holley Performance" 297 "Zonar Systems Inc" 296 "micro dynamics GmbH" 295 "BEP Marine" 294 "Grayhill Inc." 293 "Spyder Controls Corp." 292 "IKUSI - Angel Iglesias S.A." 291 "Groeneveld Transport Efficiency BV" 290 "Kuebler GmbH" 289 "Watlow" 288 "Mitsubishi FUSO Truck & Bus Corp." 287 "NTech Industries, Inc" 286 "Coelmo srl" 285 "Sea Recovery Corp" 284 "Mobile Tech Chile" 283 "CWF Hamilton & Co Ltd" 282 "Medallion Instrumentation Systems" 281 "Precision Governors LLC" 311 "Patrick Power Products" 310 "TECNORD srl" 309 "Krauss-Maffei Wegmann GmbH & Co. KG" 308 "Cyntrx" 307 "MAS Technologies" 306 "Sleipner Motor AB" 305 "NovAtel Inc" 304 "EmpirBus AB" 303 "CTS Corporation" 302 "Nissin Kogyo Co., LTD" 301 "Parker Hannifin (UK) Ltd FDE group" 300 "Systron Donner Automotive" 299 "Rauch Landmaschinen GmbH" 280 "Leica Geosystems Pty Ltd" 279 "Geometris LP" 278 "Takata Electronics" 277 "LHP Telematics" 276 "Aqua-Hot Heating Systems" 275 "Navico Egersund AS" 274 "LTW Technology Co., LTD" 273 "Active Research Limited" 272 "Gross Mechanical Laboratories, Inc" 327 "Sonceboz SA" 326 "Akron Brass Company" 325 "ASM Automation Sensorik Messtechnik GmbH" 324 "Snap-on Diagnostics" 323 "Mobileye Vision Technologies Ltd." 322 "MICHENKA s.r.o." 321 "Ultra Electronics, Electrics" 320 "Miedema Landbouwwerktuigenfabriek B.V." 319 "Cadec Global" 318 "SAT Plan" 317 "Navtronics Bvba" 316 "ITT Flow Control" 315 "Icom Incorporated" 314 "CSM GmbH" 313 "Ilmor Engineering, Inc" 312 "Lectronix, Inc." 271 "Cole Hersee" 270 "Tennant" 269 "Saft America Inc.,  Space & Defense Division" 268 "Accurate Technologies" 267 "Red Lion Controls, Inc" 266 "International Thermal Research Ltd" 265 "MTS Sensor Technologie GmbH" 264 "Autolync" 248 "Cooper Standard Automotive Active Systems Group" 247 "ePULSE" 246 "Class 1, Inc" 245 "Capstan Ag Systems, Inc." 244 "Techno-Matic" 243 "eRide, Inc." 242 "Kokusandenki Co. Ltd" 241 "Schneider Automation SAS " 240 "Vanair Mfg" 239 "May & Scofield Ltd" 238 "ZF Friedrichshafen AG" 237 "Agtron Enterprises Inc" 236 "Norac Systems International Inc" 235 "SailorMade Marine Telemetry - Tetra Technology Ltd." 234 "Mondial electronic GmbH" ;
VAL_ 2565799552 VehicleSystem 0 "Non-specific System" 127 "Not Available" ;
VAL_ 2565799552 VehicleSystem5 127 "Not Available" 0 "Ind. Process Control Stationary" ;
VAL_ 2565799552 VehicleSystem4 100 "Deck/Cargo/Fishing equip. sys" 90 "Environmental (HVAC) Systems" 80 "Instrumentation/General Systems" 70 "Communications Systems" 60 "Navigation Systems" 50 "Propulsion Systems" 40 "Steering Systems" 30 "Power Mgmt and lighting systems" 25 "Gateway" 20 "Safety Systems" 10 "System Tools" 127 "Not Available" 0 "Non-specific System" ;
VAL_ 2565799552 VehicleSystem3 8 "Grader" 7 "Four Wheel Drive Loader" 6 "Forklift" 5 "Excavator" 4 "Crawler" 3 "Backhoe" 2 "Articulated Dump Truck" 1 "Skid Steer Loader" 127 "Not Available" 0 "Non-specific System" ;
VAL_ 2565799552 VehicleSystem2 16 "Skidder" 15 "Earth Work" 14 "Special Crops" 13 "Powered Auxiliary Device" 12 "Farm Yard Operations" 11 "Transport/Trailer" 10 "Irrigation" 9 "Forage" 8 "Root Harvesters" 7 "Harvesters" 6 "Sprayers" 5 "Fertilizers" 4 "Planters/Seeders" 3 "Secondary Tillage" 2 "Tillage" 1 "Tractor" 127 "Not Available" 0 "Non-specific System" ;
VAL_ 2565799552 VehicleSystem1 2 "Trailer" 1 "Tractor" 127 "Not Available" 0 "Non-specific System" ;
VAL_ 2632777600 PGNumber 255 "NotAvailable" ;
VAL_ 2632777600 ControlByte 24 "EAbort" 23 "EEoMACK" 22 "EDPO" 21 "ECTS" 20 "ERTS" 255 "Abort" 32 "BAM" 19 "EoMA" 17 "CTS" 16 "RTS" ;
VAL_ 2560818942 FailureModeIdentifier1 31 "Not available" 19 "Received network data in error" 18 "Below normal (moderately severe)" 17 "Below normal (least severe)" 16 "Above normal (moderately severe)" 15 "Above normal (least severe)" 14 "Special intstructions" 13 "Out of calibration" 12 "Bad intelligent device" 11 "Root cause not known" 10 "Abnormal rate of change" 9 "Abnormal update rate" 8 "Abnormal frequency" 7 "Mechanical system not responding" 6 "Current above normal" 5 "Current below normal" 4 "Voltage below normal" 3 "Voltage above normal" 2 "Data erratic" 1 "Below normal (most severe)" 0 "Above normal (most severe)" ;
VAL_ 2566764798 MisfireMonitoringComplete 1 "EnabledForCycle" 0 "DisabledForRestOfCycle" ;
VAL_ 2566764798 MisfireMonitoringEnabled 1 "EnabledForCycle" 0 "DisabledForRestOfCycle" ;
VAL_ 2566764798 FuelSystemMonitoringEnabled 1 "NotCompleteCycle" 0 "CompleteCycleOrNotSupported" ;
VAL_ 2566764798 ComprehensiveComptMonComplete 1 "NotCompleteCycle" 0 "CompleteCycleOrNotSupported" ;
VAL_ 2566764798 ComprehensiveCompMonEnabled 1 "NotCompleteCycle" 0 "CompleteCycleOrNotSupported" ;
VAL_ 2566764798 SecondAirSystemMonComplete 1 "EnabledForCycle" 0 "DisabledForRestOfCycle" ;
VAL_ 2566764798 SecondAirSystemMonEnabled 1 "EnabledForCycle" 0 "DisabledForRestOfCycle" ;
VAL_ 2566764798 OxygenSensorMonComplete 1 "EnabledForCycle" 0 "DisabledForRestOfCycle" ;
VAL_ 2566764798 OxygenSensorMonEnabled 1 "NotCompleteCycle" 0 "CompleteCycleOrNotSupported" ;
VAL_ 2566764798 OxygenSensorHeaterMonComplete 1 "EnabledForCycle" 0 "DisabledForRestOfCycle" ;
VAL_ 2566764798 OxygenSensorHeaterMonEnabled 1 "NotCompleteCycle" 0 "CompleteCycleOrNotSupported" ;
VAL_ 2566764798 HeatedCatalystMonComplete 1 "EnabledForCycle" 0 "DisabledForRestOfCycle" ;
VAL_ 2566764798 HeatedCatalystMonEnabled 1 "EnabledForCycle" 0 "DisabledForRestOfCycle" ;
VAL_ 2566764798 EvaporativeSystemMonComplete 1 "NotCompleteCycle" 0 "CompleteCycleOrNotSupported" ;
VAL_ 2566764798 EvaporativeSystemMonEnabled 1 "NotCompleteCycle" 0 "CompleteCycleOrNotSupported" ;
VAL_ 2566764798 EGRSystemMonitoringComplete 1 "NotCompleteCycle" 0 "CompleteCycleOrNotSupported" ;
VAL_ 2566764798 EGRSystemMonitoringEnabled 1 "EnabledForCycle" 0 "DisabledForRestOfCycle" ;
VAL_ 2566764798 ColdStartAidSystemMonComplete 1 "EnabledForCycle" 0 "DisabledForRestOfCycle" ;
VAL_ 2566764798 ColdStartAidSystemMonEnabled 1 "EnabledForCycle" 0 "DisabledForRestOfCycle" ;
VAL_ 2566764798 CatalystMonComplete 1 "NotCompleteCycle" 0 "CompleteCycleOrNotSupported" ;
VAL_ 2566764798 CatalystMonEnabled 1 "NotCompleteCycle" 0 "CompleteCycleOrNotSupported" ;
VAL_ 2566764798 ACSystemRefrigerantMonComplete 1 "NotCompleteCycle" 0 "CompleteCycleOrNotSupported" ;
VAL_ 2566764798 ACSystemRefrigerantMonEnabled 1 "NotCompleteCycle" 0 "CompleteCycleOrNotSupported" ;
VAL_ 2566764798 FuelSystemMonitoringComplete 1 "NotCompleteCycle" 0 "CompleteCycleOrNotSupported" ;
VAL_ 2564095742 SecurityEntityType 3 "Data is Certificate" 2 "Data is Session Key" 1 "Data is Long Key" 0 "Data is Long Seed" ;
VAL_ 2566742270 FailureModeIdentifier1 31 "Not available" 19 "Received network data in error" 18 "Below normal (moderately severe)" 17 "Below normal (least severe)" 16 "Above normal (moderately severe)" 15 "Above normal (least severe)" 14 "Special intstructions" 13 "Out of calibration" 12 "Bad intelligent device" 11 "Root cause not known" 10 "Abnormal rate of change" 9 "Abnormal update rate" 8 "Abnormal frequency" 7 "Mechanical system not responding" 6 "Current above normal" 5 "Current below normal" 4 "Voltage below normal" 3 "Voltage above normal" 2 "Data erratic" 1 "Below normal (most severe)" 0 "Above normal (most severe)" ;
VAL_ 2560687870 PMNTEDeficiencyAreaStatus 3 "NotAvailable" 2 "Reserved" 1 "InsideControlArea" 0 "OutsideControlArea" ;
VAL_ 2560687870 MnfcPMNTECarveOutAreaStatus 3 "NotAvailable" 2 "Reserved" 1 "InsideControlArea" 0 "OutsideControlArea" ;
VAL_ 2560687870 PMNTEControlAreaStatus 3 "NotAvailable" 2 "Reserved" 1 "InsideControlArea" 0 "OutsideControlArea" ;
VAL_ 2560687870 NOxNTEDeficiencyAreaStatus 3 "NotAvailable" 2 "Reserved" 1 "InsideControlArea" 0 "OutsideControlArea" ;
VAL_ 2560687870 MnfcNOxNTECarveOutAreaStatus 3 "NotAvailable" 2 "Reserved" 1 "InsideControlArea" 0 "OutsideControlArea" ;
VAL_ 2560687870 NOxNTEControlAreaStatus 3 "NotAvailable" 2 "Reserved" 1 "InsideControlArea" 0 "OutsideControlArea" ;
VAL_ 2560884478 DTCWarnLampSupportStatus 3 "Unavailable" 2 "Reserved" 1 "LampOn" 0 "LampOff" ;
VAL_ 2560884478 DTCWarnLampSupportFlash 3 "Unavailable" 2 "Reserved" 1 "FastFlash" 0 "SlowFlash" ;
VAL_ 2560884478 DTCStopLampSupportStatus 3 "Unavailable" 2 "Reserved" 1 "LampOn" 0 "LampOff" ;
VAL_ 2560884478 DTCStopLampSupportFlash 3 "Unavailable" 2 "Reserved" 1 "FastFlash" 0 "SlowFlash" ;
VAL_ 2560884478 DTCProtectLampSupportStatus 3 "Unavailable" 2 "Reserved" 1 "LampOn" 0 "LampOff" ;
VAL_ 2560884478 DTCProtectLampSupportFlash 3 "Unavailable" 2 "Reserved" 1 "FastFlash" 0 "SlowFlash" ;
VAL_ 2560884478 DTCMilSupportStatus 3 "Unavailable" 2 "ShortMI" 1 "LampOn" 0 "LampOff" ;
VAL_ 2560884478 DTCMilSupportFlash 3 "Unavailable" 2 "Class_C_DTC" 1 "FastFlash" 0 "SlowFlash" ;
VAL_ 2560950014 FailureModeIdentifier1 31 "Not available" 19 "Received network data in error" 18 "Below normal (moderately severe)" 17 "Below normal (least severe)" 16 "Above normal (moderately severe)" 15 "Above normal (least severe)" 14 "Special intstructions" 13 "Out of calibration" 12 "Bad intelligent device" 11 "Root cause not known" 10 "Abnormal rate of change" 9 "Abnormal update rate" 8 "Abnormal frequency" 7 "Mechanical system not responding" 6 "Current above normal" 5 "Current below normal" 4 "Voltage below normal" 3 "Voltage above normal" 2 "Data erratic" 1 "Below normal (most severe)" 0 "Above normal (most severe)" ;
VAL_ 2566836478 TestIdentifier 250 "Last Measured Scaled Results" 249 "Command Standard Test" 247 "All scaled test results" ;
VAL_ 2565078782 TestIdentifier 250 "Last Measured Scaled Results" 249 "Command Standard Test" 247 "All scaled test results" ;
VAL_ 2565078782 FailureModeIdentifier1 31 "Not available" 19 "Received network data in error" 18 "Below normal (moderately severe)" 17 "Below normal (least severe)" 16 "Above normal (moderately severe)" 15 "Above normal (least severe)" 14 "Special intstructions" 13 "Out of calibration" 12 "Bad intelligent device" 11 "Root cause not known" 10 "Abnormal rate of change" 9 "Abnormal update rate" 8 "Abnormal frequency" 7 "Mechanical system not responding" 6 "Current above normal" 5 "Current below normal" 4 "Voltage below normal" 3 "Voltage above normal" 2 "Data erratic" 1 "Below normal (most severe)" 0 "Above normal (most severe)" ;
VAL_ 2566836222 FlashRedStopLamp 3 "Unavailable / Do Not Flash" 2 "Reserved" 1 "Fast Flash" 0 "Slow Flash" ;
VAL_ 2566836222 FlashProtectLamp 3 "Unavailable / Do Not Flash" 2 "Reserved" 1 "Fast Flash" 0 "Slow Flash" ;
VAL_ 2566836222 FlashMalfuncIndicatorLamp 3 "Unavailable / Do Not Flash" 2 "Reserved" 1 "Fast Flash" 0 "Slow Flash" ;
VAL_ 2566836222 FlashAmberWarningLamp 3 "Unavailable / Do Not Flash" 2 "Reserved" 1 "Fast Flash" 0 "Slow Flash" ;
VAL_ 2566836222 MalfunctionIndicatorLampStatus 3 "Not available" 2 "Reserved" 1 "Lamp on" 0 "Lamp off" ;
VAL_ 2566836222 RedStopLampState 3 "Not available" 2 "Reserved" 1 "Lamp on" 0 "Lamp off" ;
VAL_ 2566836222 AmberWarningLampStatus 3 "Not available" 2 "Reserved" 1 "Lamp on" 0 "Lamp off" ;
VAL_ 2566836222 ProtectLampStatus 3 "Not available" 2 "Reserved" 1 "Lamp on" 0 "Lamp off" ;
VAL_ 2566835966 MisfireMonitoringSupport 3 "Not available" 2 "Reserved" 1 "test supported" 0 "test not supported" ;
VAL_ 2566835966 OBDCompliance 10 "JOBD" 11 "JOBD and OBD II" 12 "JOBD and EOBD" 13 "JOBD, EOBD and OBD II" 14 "Heavy Duty Vehicles (EURO IV) B1" 15 "Heavy Duty Vehicles (EURO V) B2" 16 "Heavy Duty Vehicles (EURO EEC) C" 17 "EMD" 18 "EMD+" 19 "HD OBD P" 20 "HD OBD" 21 "WWH OBD" 22 "OBD II (California, ARB 07/08)" 23 "HD EOBD" 25 "OBD-M (SI-SD/I)" 6 "EOBD" 7 "EOBD and OBD II" 8 "EOBD and OBD" 9 "EOBD, OBD and OBD II" 5 "Not intended to meet OBD II req." 4 "OBD I" 3 "OBD and OBD II" 2 "OBD (Federal, EPA)" 1 "OBD II (California, ARB)" 0 "Reserver for assignment by SAE" ;
VAL_ 2566835966 SecondAirSystemMonStatus 1 "TestNotComplete" 0 "TestComplete" ;
VAL_ 2566835966 EvaporativeSystemMonStatus 1 "TestNotComplete" 0 "TestComplete" ;
VAL_ 2566835966 ACSystemRefrigerantMonStatus 1 "TestNotComplete" 0 "TestComplete" ;
VAL_ 2566835966 OxygenSensorHeaterMonStatus 1 "TestNotComplete" 0 "TestComplete" ;
VAL_ 2566835966 OxygenSensorMonStatus 1 "test not complete" 0 "test complete" ;
VAL_ 2566835966 EGRSystemMonitoringStatus 1 "TestNotComplete" 0 "TestComplete" ;
VAL_ 2566835966 CatalystMonStatus 0 "TestComplete" 1 "TestNotComplete" ;
VAL_ 2566835966 ColdStartAidSystemMonStatus 1 "TestNotComplete" 0 "TestComplete" ;
VAL_ 2566835966 HeatedCatalystMonStatus 1 "TestNotComplete" 0 "TestComplete" ;
VAL_ 2566835966 CatalystMonSupp 1 "TestSupported" 0 "TestNotSupported" ;
VAL_ 2566835966 ColdStartAidSystemMonSupp 1 "TestSupported" 0 "TestNotSupported" ;
VAL_ 2566835966 HeatedCatalystMonSupp 1 "TestSupported" 0 "TestNotSupported" ;
VAL_ 2566835966 EvaporativeSystemMonSupp 1 "TestSupported" 0 "TestNotSupported" ;
VAL_ 2566835966 SecondAirSystemMonSupp 1 "TestSupported" 0 "TestNotSupported" ;
VAL_ 2566835966 ACSystemRefrigerantMonSupp 1 "TestSupported" 0 "TestNotSupported" ;
VAL_ 2566835966 OxygenSensorMonSupp 1 "TestSupported" 0 "TestNotSupported" ;
VAL_ 2566835966 OxygenSensorHeaterMonSupp 1 "TestSupported" 0 "TestNotSupported" ;
VAL_ 2566835966 EGRSystemMonitoringSupp 1 "TestSupported" 0 "TestNotSupported" ;
VAL_ 2566835966 MisfireMonitoringStatus 1 "test not complete" 0 "test complete" ;
VAL_ 2566835966 ComprehensiveCompMonStatus 1 "test not complete" 0 "test complete" ;
VAL_ 2566835966 FuelSystemMonitoringStatus 1 "test not complete" 0 "test complete" ;
VAL_ 2566835966 ComprehensiveComponentMonSupp 3 "Not available" 2 "Reserved" 1 "test supported" 0 "test not supported" ;
VAL_ 2566835966 FuelSystemMonitoringSupport 1 "test supported" 0 "test not supported" ;
VAL_ 2566764286 SPNSupportTypeSTR3 1 "NotSupportedInScaledTestResults" 0 "SupportedInScaledTestResults" ;
VAL_ 2566764286 SPNSupportTypeSTR2 1 "NotSupportedInScaledTestResults" 0 "SupportedInScaledTestResults" ;
VAL_ 2566764286 SPNSupportTypeEFF3 1 "NotSupportedInExFreezeFrame" 0 "SupportedInExFreezeFrame" ;
VAL_ 2566764286 SPNSupportTypeEFF2 1 "NotSupportedInExFreezeFrame" 0 "SupportedInExFreezeFrame" ;
VAL_ 2566764286 SPNSupportTypeDS3 1 "NotSupportedInDataStream" 0 "SupportedInDataStream" ;
VAL_ 2566764286 SPNSupportTypeDS2 1 "NotSupportedInDataStream" 0 "SupportedInDataStream" ;
VAL_ 2566764286 SPNSupportTypeSTR1 1 "NotSupportedInScaledTestResults" 0 "SupportedInScaledTestResults" ;
VAL_ 2566764286 SPNSupportTypeDS1 1 "NotSupportedInDataStream" 0 "SupportedInDataStream" ;
VAL_ 2566764286 SPNSupportTypeEFF1 1 "NotSupportedInExFreezeFrame" 0 "SupportedInExFreezeFrame" ;
